VERSION "dbc-export 1 2025.20.8"

NS_ :

BS_:

BU_: APP APS DAS EPAS3S ESP GTW IBST PARK RADC RCM TPMS USM

BO_ 606 PARK_pscEnvSlot: 8 PARK
 SG_ PARK_pscEnvSlotType M : 0|2@1+ (1,0) [0|3] "" Vector__XXX
 SG_ PARK_pscLeftParallelObj1X m0 : 3|11@1+ (2,-2048) [-2048|2044] "cm" Vector__XXX
 SG_ PARK_pscLeftParallelObj1Y m0 : 14|11@1+ (2,-2048) [-2048|2044] "cm" Vector__XXX
 SG_ PARK_pscLeftParallelObj1Alpha m0 : 25|7@1+ (2,-128) [-128|124] "deg" Vector__XXX
 SG_ PARK_pscLeftParallelObj2Y m0 : 35|11@1+ (2,-2048) [-2048|2044] "cm" Vector__XXX
 SG_ PARK_pscLeftParallelObj2X m0 : 46|11@1+ (2,-2048) [-2048|2044] "cm" Vector__XXX
 SG_ PARK_pscLeftParallelObj2Alpha m0 : 57|7@1+ (2,-128) [-128|124] "deg" Vector__XXX
 SG_ PARK_pscLeftCrossObj1X m1 : 3|11@1+ (2,-2048) [-2048|2044] "cm" Vector__XXX
 SG_ PARK_pscLeftCrossObj1Y m1 : 14|11@1+ (2,-2048) [-2048|2044] "cm" Vector__XXX
 SG_ PARK_pscLeftCrossObj1Alpha m1 : 25|7@1+ (2,-128) [-128|124] "deg" Vector__XXX
 SG_ PARK_pscLeftCrossObj2Y m1 : 35|11@1+ (2,-2048) [-2048|2044] "cm" Vector__XXX
 SG_ PARK_pscLeftCrossObj2X m1 : 46|11@1+ (2,-2048) [-2048|2044] "cm" Vector__XXX
 SG_ PARK_pscLeftCrossObj2Alpha m1 : 57|7@1+ (2,-128) [-128|124] "deg" Vector__XXX
 SG_ PARK_pscRightParallelObj1X m2 : 3|11@1+ (2,-2048) [-2048|2044] "cm" Vector__XXX
 SG_ PARK_pscRightParallelObj1Y m2 : 14|11@1+ (2,-2048) [-2048|2044] "cm" Vector__XXX
 SG_ PARK_pscRightParallelObj1Alpha m2 : 25|7@1+ (2,-128) [-128|124] "deg" Vector__XXX
 SG_ PARK_pscRightParallelObj2Y m2 : 35|11@1+ (2,-2048) [-2048|2044] "cm" Vector__XXX
 SG_ PARK_pscRightParallelObj2X m2 : 46|11@1+ (2,-2048) [-2048|2044] "cm" Vector__XXX
 SG_ PARK_pscRightParallelObj2Alpha m2 : 57|7@1+ (2,-128) [-128|124] "deg" Vector__XXX
 SG_ PARK_pscRightCrossObj1X m3 : 3|11@1+ (2,-2048) [-2048|2044] "cm" Vector__XXX
 SG_ PARK_pscRightCrossObj1Y m3 : 14|11@1+ (2,-2048) [-2048|2044] "cm" Vector__XXX
 SG_ PARK_pscRightCrossObj1Alpha m3 : 25|7@1+ (2,-128) [-128|124] "deg" Vector__XXX
 SG_ PARK_pscRightCrossObj2Y m3 : 35|11@1+ (2,-2048) [-2048|2044] "cm" Vector__XXX
 SG_ PARK_pscRightCrossObj2X m3 : 46|11@1+ (2,-2048) [-2048|2044] "cm" Vector__XXX
 SG_ PARK_pscRightCrossObj2Alpha m3 : 57|7@1+ (2,-128) [-128|124] "deg" Vector__XXX

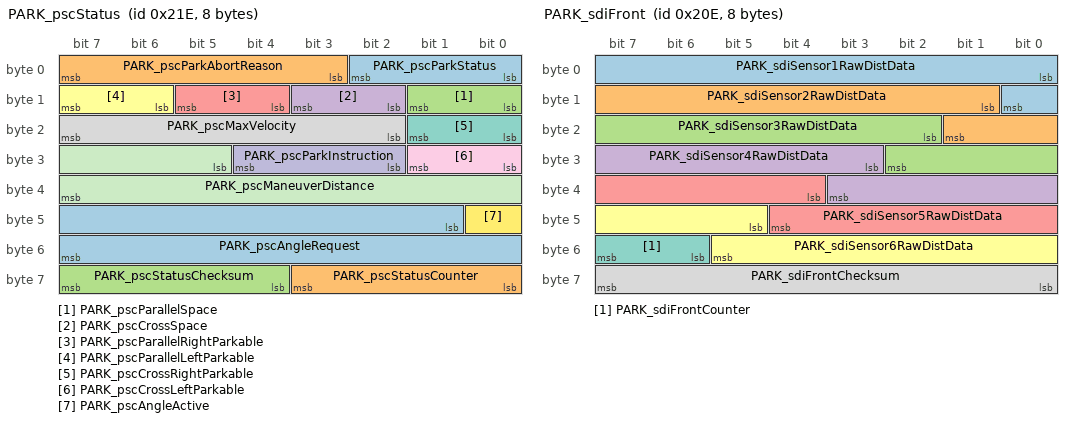
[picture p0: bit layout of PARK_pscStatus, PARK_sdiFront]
BO_ 542 PARK_pscStatus: 8 PARK
 SG_ PARK_pscParkStatus : 0|3@1+ (1,0) [0|6] "" Vector__XXX
 SG_ PARK_pscParkAbortReason : 3|5@1+ (1,0) [0|30] "" Vector__XXX
 SG_ PARK_pscParallelSpace : 8|2@1+ (1,0) [0|3] "" Vector__XXX
 SG_ PARK_pscCrossSpace : 10|2@1+ (1,0) [0|3] "" Vector__XXX
 SG_ PARK_pscParallelRightParkable : 12|2@1+ (1,0) [0|2] "" Vector__XXX
 SG_ PARK_pscParallelLeftParkable : 14|2@1+ (1,0) [0|2] "" Vector__XXX
 SG_ PARK_pscCrossRightParkable : 16|2@1+ (1,0) [0|2] "" Vector__XXX
 SG_ PARK_pscMaxVelocity : 18|6@1+ (0.1,0) [0|6.2] "kph" Vector__XXX
 SG_ PARK_pscCrossLeftParkable : 24|2@1+ (1,0) [0|2] "" Vector__XXX
 SG_ PARK_pscParkInstruction : 26|3@1+ (1,0) [0|6] "" Vector__XXX
 SG_ PARK_pscManeuverDistance : 29|11@1+ (1,0) [0|2046] "cm" Vector__XXX
 SG_ PARK_pscAngleActive : 40|1@1+ (1,0) [0|1] "" Vector__XXX
 SG_ PARK_pscAngleRequest : 41|15@1+ (0.1,-1638.4) [-1638.4|1638.3] "deg" Vector__XXX
 SG_ PARK_pscStatusCounter : 56|4@1+ (1,0) [0|15] "" Vector__XXX
 SG_ PARK_pscStatusChecksum : 60|4@1+ (1,0) [0|15] "" Vector__XXX

BO_ 590 PARK_pscVehSlot: 8 PARK
 SG_ PARK_pscVehSlotType M : 0|2@1+ (1,0) [0|3] "" Vector__XXX
 SG_ PARK_pscLeftParallelVehX m0 : 5|11@1+ (2,-2048) [-2048|2044] "cm" Vector__XXX
 SG_ PARK_pscLeftParallelVehY m0 : 16|11@1+ (2,-2048) [-2048|2044] "cm" Vector__XXX
 SG_ PARK_pscLeftParallelPsi m0 : 32|13@1+ (0.0009765625,0) [0|7.998046875] "radians" Vector__XXX
 SG_ PARK_pscLeftParallelSizeX m0 : 48|8@1+ (4,0) [0|1016] "cm" Vector__XXX
 SG_ PARK_pscLeftParallelSizeY m0 : 56|8@1+ (4,0) [0|1016] "cm" Vector__XXX
 SG_ PARK_pscLeftCrossVehX m1 : 5|11@1+ (2,-2048) [-2048|2044] "cm" Vector__XXX
 SG_ PARK_pscLeftCrossVehY m1 : 16|11@1+ (2,-2048) [-2048|2044] "cm" Vector__XXX
 SG_ PARK_pscLeftCrossPsi m1 : 32|13@1+ (0.0009765625,0) [0|7.998046875] "radians" Vector__XXX
 SG_ PARK_pscLeftCrossSizeX m1 : 48|8@1+ (4,0) [0|1016] "cm" Vector__XXX
 SG_ PARK_pscLeftCrossSizeY m1 : 56|8@1+ (4,0) [0|1016] "cm" Vector__XXX
 SG_ PARK_pscRightParallelVehX m2 : 5|11@1+ (2,-2048) [-2048|2044] "cm" Vector__XXX
 SG_ PARK_pscRightParallelVehY m2 : 16|11@1+ (2,-2048) [-2048|2044] "cm" Vector__XXX
 SG_ PARK_pscRightParallelPsi m2 : 32|13@1+ (0.0009765625,0) [0|7.998046875] "radians" Vector__XXX
 SG_ PARK_pscRightParallelSizeX m2 : 48|8@1+ (4,0) [0|1016] "cm" Vector__XXX
 SG_ PARK_pscRightParallelSizeY m2 : 56|8@1+ (4,0) [0|1016] "cm" Vector__XXX
 SG_ PARK_pscRightCrossVehX m3 : 5|11@1+ (2,-2048) [-2048|2044] "cm" Vector__XXX
 SG_ PARK_pscRightCrossVehY m3 : 16|11@1+ (2,-2048) [-2048|2044] "cm" Vector__XXX
 SG_ PARK_pscRightCrossPsi m3 : 32|13@1+ (0.0009765625,0) [0|7.998046875] "radians" Vector__XXX
 SG_ PARK_pscRightCrossSizeX m3 : 48|8@1+ (4,0) [0|1016] "cm" Vector__XXX
 SG_ PARK_pscRightCrossSizeY m3 : 56|8@1+ (4,0) [0|1016] "cm" Vector__XXX

BO_ 526 PARK_sdiFront: 8 PARK
 SG_ PARK_sdiSensor1RawDistData : 0|9@1+ (1,0) [0|510] "cm" Vector__XXX
 SG_ PARK_sdiSensor2RawDistData : 9|9@1+ (1,0) [0|510] "cm" Vector__XXX
 SG_ PARK_sdiSensor3RawDistData : 18|9@1+ (1,0) [0|510] "cm" Vector__XXX
 SG_ PARK_sdiSensor4RawDistData : 27|9@1+ (1,0) [0|510] "cm" Vector__XXX
 SG_ PARK_sdiSensor5RawDistData : 36|9@1+ (1,0) [0|510] "cm" Vector__XXX
 SG_ PARK_sdiSensor6RawDistData : 45|9@1+ (1,0) [0|510] "cm" Vector__XXX
 SG_ PARK_sdiFrontCounter : 54|2@1+ (1,0) [0|3] "" Vector__XXX
 SG_ PARK_sdiFrontChecksum : 56|8@1+ (1,0) [0|255] "" Vector__XXX

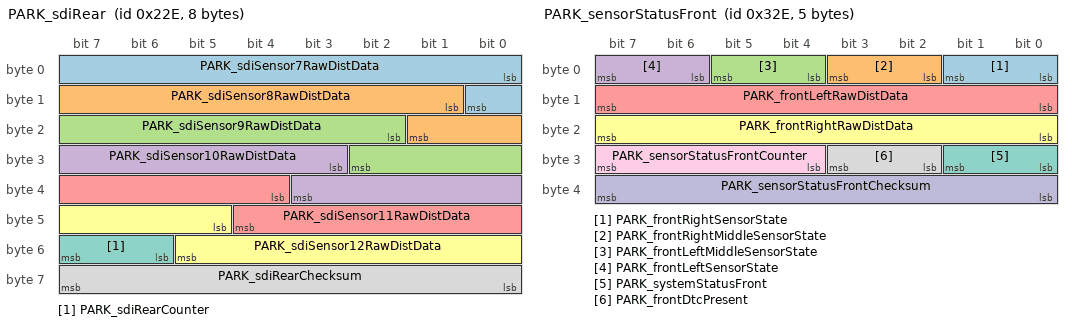
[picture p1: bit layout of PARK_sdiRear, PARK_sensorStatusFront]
BO_ 558 PARK_sdiRear: 8 PARK
 SG_ PARK_sdiSensor7RawDistData : 0|9@1+ (1,0) [0|510] "cm" Vector__XXX
 SG_ PARK_sdiSensor8RawDistData : 9|9@1+ (1,0) [0|510] "cm" Vector__XXX
 SG_ PARK_sdiSensor9RawDistData : 18|9@1+ (1,0) [0|510] "cm" Vector__XXX
 SG_ PARK_sdiSensor10RawDistData : 27|9@1+ (1,0) [0|510] "cm" Vector__XXX
 SG_ PARK_sdiSensor11RawDistData : 36|9@1+ (1,0) [0|510] "cm" Vector__XXX
 SG_ PARK_sdiSensor12RawDistData : 45|9@1+ (1,0) [0|510] "cm" Vector__XXX
 SG_ PARK_sdiRearCounter : 54|2@1+ (1,0) [0|3] "" Vector__XXX
 SG_ PARK_sdiRearChecksum : 56|8@1+ (1,0) [0|255] "" Vector__XXX

BO_ 814 PARK_sensorStatusFront: 5 PARK
 SG_ PARK_frontRightSensorState : 0|2@1+ (1,0) [0|2] "" Vector__XXX
 SG_ PARK_frontRightMiddleSensorState : 2|2@1+ (1,0) [0|2] "" Vector__XXX
 SG_ PARK_frontLeftMiddleSensorState : 4|2@1+ (1,0) [0|2] "" Vector__XXX
 SG_ PARK_frontLeftSensorState : 6|2@1+ (1,0) [0|2] "" Vector__XXX
 SG_ PARK_frontLeftRawDistData : 8|8@1+ (1,0) [0|254] "cm" Vector__XXX
 SG_ PARK_frontRightRawDistData : 16|8@1+ (1,0) [0|254] "cm" Vector__XXX
 SG_ PARK_systemStatusFront : 24|2@1+ (1,0) [0|2] "" Vector__XXX
 SG_ PARK_frontDtcPresent : 26|2@1+ (1,0) [0|2] "" Vector__XXX
 SG_ PARK_sensorStatusFrontCounter : 28|4@1+ (1,0) [0|15] "" Vector__XXX
 SG_ PARK_sensorStatusFrontChecksum : 32|8@1+ (1,0) [0|255] "" Vector__XXX

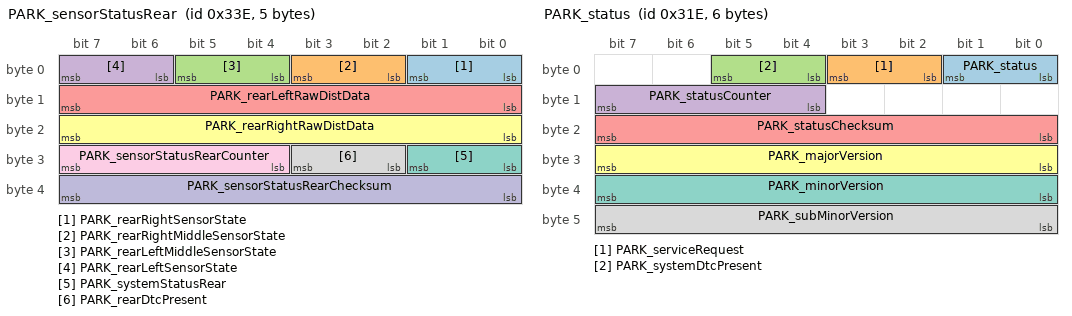
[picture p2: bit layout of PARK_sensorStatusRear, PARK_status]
BO_ 830 PARK_sensorStatusRear: 5 PARK
 SG_ PARK_rearRightSensorState : 0|2@1+ (1,0) [0|2] "" Vector__XXX
 SG_ PARK_rearRightMiddleSensorState : 2|2@1+ (1,0) [0|2] "" Vector__XXX
 SG_ PARK_rearLeftMiddleSensorState : 4|2@1+ (1,0) [0|2] "" Vector__XXX
 SG_ PARK_rearLeftSensorState : 6|2@1+ (1,0) [0|2] "" Vector__XXX
 SG_ PARK_rearLeftRawDistData : 8|8@1+ (1,0) [0|254] "cm" Vector__XXX
 SG_ PARK_rearRightRawDistData : 16|8@1+ (1,0) [0|254] "cm" Vector__XXX
 SG_ PARK_systemStatusRear : 24|2@1+ (1,0) [0|2] "" Vector__XXX
 SG_ PARK_rearDtcPresent : 26|2@1+ (1,0) [0|2] "" Vector__XXX
 SG_ PARK_sensorStatusRearCounter : 28|4@1+ (1,0) [0|15] "" Vector__XXX
 SG_ PARK_sensorStatusRearChecksum : 32|8@1+ (1,0) [0|255] "" Vector__XXX

BO_ 798 PARK_status: 6 PARK
 SG_ PARK_status : 0|2@1+ (1,0) [0|2] "" Vector__XXX
 SG_ PARK_serviceRequest : 2|2@1+ (1,0) [0|2] "" Vector__XXX
 SG_ PARK_systemDtcPresent : 4|2@1+ (1,0) [0|2] "" Vector__XXX
 SG_ PARK_statusCounter : 12|4@1+ (1,0) [0|15] "" Vector__XXX
 SG_ PARK_statusChecksum : 16|8@1+ (1,0) [0|255] "" Vector__XXX
 SG_ PARK_majorVersion : 24|8@1+ (1,0) [0|254] "" Vector__XXX
 SG_ PARK_minorVersion : 32|8@1+ (1,0) [0|254] "" Vector__XXX
 SG_ PARK_subMinorVersion : 40|8@1+ (1,0) [0|254] "" Vector__XXX

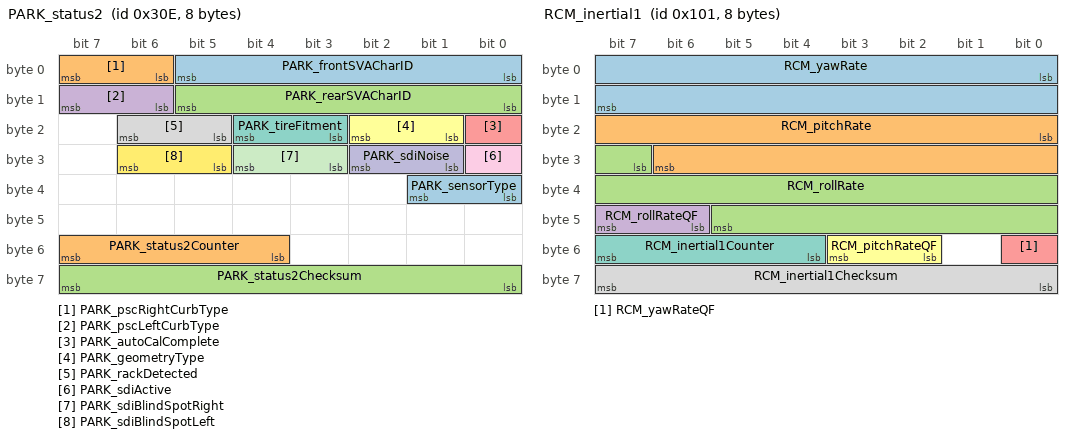
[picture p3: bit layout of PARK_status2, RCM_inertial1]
BO_ 782 PARK_status2: 8 PARK
 SG_ PARK_frontSVACharID : 0|6@1+ (1,0) [0|63] "" Vector__XXX
 SG_ PARK_pscRightCurbType : 6|2@1+ (1,0) [0|3] "" Vector__XXX
 SG_ PARK_rearSVACharID : 8|6@1+ (1,0) [0|63] "" Vector__XXX
 SG_ PARK_pscLeftCurbType : 14|2@1+ (1,0) [0|3] "" Vector__XXX
 SG_ PARK_autoCalComplete : 16|1@1+ (1,0) [0|1] "" Vector__XXX
 SG_ PARK_geometryType : 17|2@1+ (1,0) [0|3] "" Vector__XXX
 SG_ PARK_tireFitment : 19|2@1+ (1,0) [0|2] "" Vector__XXX
 SG_ PARK_rackDetected : 21|2@1+ (1,0) [0|2] "" Vector__XXX
 SG_ PARK_sdiActive : 24|1@1+ (1,0) [0|1] "" Vector__XXX
 SG_ PARK_sdiNoise : 25|2@1+ (1,0) [0|2] "" Vector__XXX
 SG_ PARK_sdiBlindSpotRight : 27|2@1+ (1,0) [0|2] "" Vector__XXX
 SG_ PARK_sdiBlindSpotLeft : 29|2@1+ (1,0) [0|2] "" Vector__XXX
 SG_ PARK_sensorType : 32|2@1+ (1,0) [0|2] "" Vector__XXX
 SG_ PARK_status2Counter : 52|4@1+ (1,0) [0|15] "" Vector__XXX
 SG_ PARK_status2Checksum : 56|8@1+ (1,0) [0|255] "" Vector__XXX

BO_ 1329 RADC_info: 8 RADC
 SG_ RADC_infoIndex M : 0|8@1+ (1,0) [0|255] "" Vector__XXX
 SG_ RADC_infoBuildType m10 : 8|8@1+ (1,0) [0|255] "" Vector__XXX
 SG_ RADC_infoBuildConfigID m10 : 16|16@1+ (1,0) [0|65535] "" Vector__XXX
 SG_ RADC_infoHardwareID m10 : 32|16@1+ (1,0) [0|65535] "" Vector__XXX
 SG_ RADC_infoComponentID m10 : 48|16@1+ (1,0) [0|65535] "" Vector__XXX
 SG_ RADC_infoPcbaID m11 : 16|8@1+ (1,0) [0|255] "" Vector__XXX
 SG_ RADC_infoAssemblyID m11 : 24|8@1+ (1,0) [0|255] "" Vector__XXX
 SG_ RADC_infoUsageID m11 : 32|16@1+ (1,0) [0|65535] "" Vector__XXX
 SG_ RADC_infoSubUsageID m11 : 48|16@1+ (1,0) [0|65535] "" Vector__XXX
 SG_ RADC_infoApplicationCRC m13 : 32|32@1+ (1,0) [0|4294967295] "" Vector__XXX
 SG_ RADC_infoPlatformType m19 : 8|8@1+ (1,0) [0|255] "" Vector__XXX
 SG_ RADC_infoMajorVersion m19 : 16|8@1+ (1,0) [0|255] "" Vector__XXX
 SG_ RADC_infoBranchOrigin m19 : 24|8@1+ (1,0) [0|255] "" Vector__XXX
 SG_ RADC_infoMaturity m19 : 32|8@1+ (1,0) [0|255] "" Vector__XXX
 SG_ RADC_infoHardwareRevision m19 : 40|8@1+ (1,0) [0|255] "" Vector__XXX
 SG_ RADC_infoBootUdsProtoVersion m20 : 8|8@1+ (1,0) [0|255] "" Vector__XXX
 SG_ RADC_infoBootloaderCRC m20 : 32|32@1+ (1,0) [0|4294967295] "" Vector__XXX

BO_ 257 RCM_inertial1: 8 RCM
 SG_ RCM_yawRate : 0|16@1- (0.0001,0) [-3.2766|3.2766] "rad/s" Vector__XXX
 SG_ RCM_pitchRate : 16|15@1- (0.00025,0) [-4.096|4.09575] "rad/s" Vector__XXX
 SG_ RCM_rollRate : 31|15@1- (0.00025,0) [-4.096|4.09575] "rad/s" Vector__XXX
 SG_ RCM_rollRateQF : 46|2@1+ (1,0) [0|3] "" Vector__XXX
 SG_ RCM_yawRateQF : 48|1@1+ (1,0) [0|1] "" Vector__XXX
 SG_ RCM_pitchRateQF : 50|2@1+ (1,0) [0|3] "" Vector__XXX
 SG_ RCM_inertial1Counter : 52|4@1+ (1,0) [0|15] "" Vector__XXX
 SG_ RCM_inertial1Checksum : 56|8@1+ (1,0) [0|255] "" Vector__XXX

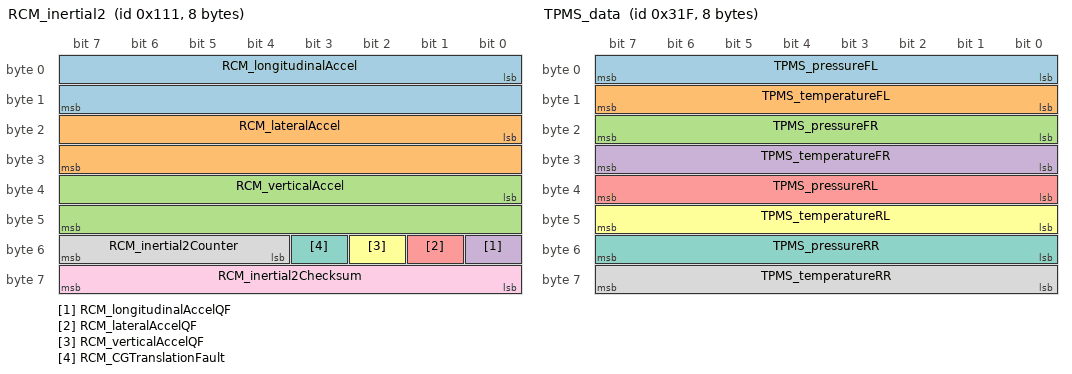
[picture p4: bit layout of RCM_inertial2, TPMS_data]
BO_ 273 RCM_inertial2: 8 RCM
 SG_ RCM_longitudinalAccel : 0|16@1- (0.00125,0) [-40.9575|40.9575] "m/s^2" Vector__XXX
 SG_ RCM_lateralAccel : 16|16@1- (0.00125,0) [-40.9575|40.9575] "m/s^2" Vector__XXX
 SG_ RCM_verticalAccel : 32|16@1- (0.00125,0) [-40.9575|39.2] "m/s^2" Vector__XXX
 SG_ RCM_longitudinalAccelQF : 48|1@1+ (1,0) [0|1] "" Vector__XXX
 SG_ RCM_lateralAccelQF : 49|1@1+ (1,0) [0|1] "" Vector__XXX
 SG_ RCM_verticalAccelQF : 50|1@1+ (1,0) [0|1] "" Vector__XXX
 SG_ RCM_CGTranslationFault : 51|1@1+ (1,0) [0|1] "" Vector__XXX
 SG_ RCM_inertial2Counter : 52|4@1+ (1,0) [0|15] "" Vector__XXX
 SG_ RCM_inertial2Checksum : 56|8@1+ (1,0) [0|255] "" Vector__XXX

BO_ 849 RCM_info: 8 RCM
 SG_ RCM_infoIndex M : 0|8@1+ (1,0) [0|255] "" Vector__XXX
 SG_ RCM_infoBuildType m10 : 8|8@1+ (1,0) [0|255] "" Vector__XXX
 SG_ RCM_infoComponentID m10 : 48|16@1+ (1,0) [0|65535] "" Vector__XXX
 SG_ RCM_infoPcbaID m11 : 16|8@1+ (1,0) [0|255] "" Vector__XXX
 SG_ RCM_infoAssemblyID m11 : 24|8@1+ (1,0) [0|255] "" Vector__XXX
 SG_ RCM_infoUsageID m11 : 32|16@1+ (1,0) [0|65535] "" Vector__XXX
 SG_ RCM_infoApplicationCRC m13 : 32|32@1+ (1,0) [0|4294967295] "" Vector__XXX
 SG_ RCM_infoBootUdsProtoVersion m20 : 8|8@1+ (1,0) [0|255] "" Vector__XXX
 SG_ RCM_infoBootloaderCRC m20 : 32|32@1+ (1,0) [0|4294967295] "" Vector__XXX
 SG_ RCM_infoAlgoCalID m22 : 8|8@1+ (1,0) [0|255] "" Vector__XXX
 SG_ RCM_infoVariantCRC m22 : 32|32@1+ (1,0) [0|4294967295] "" Vector__XXX

BO_ 529 RCM_status: 6 RCM
 SG_ RCM_statusChecksum : 0|8@1+ (1,0) [0|255] "" Vector__XXX
 SG_ RCM_statusCounter : 8|4@1+ (1,0) [0|15] "" Vector__XXX
 SG_ RCM_armStatus : 12|2@1+ (1,0) [0|2] "" Vector__XXX
 SG_ RCM_warningIndicatorState : 14|2@1+ (1,0) [0|2] "" Vector__XXX
 SG_ RCM_passAirbagIndicatorRequest : 16|2@1+ (1,0) [0|2] "" Vector__XXX
 SG_ RCM_airbagCutoffStatus : 18|2@1+ (1,0) [0|2] "" Vector__XXX
 SG_ RCM_alrSwitchStatus : 20|2@1+ (1,0) [0|2] "" Vector__XXX
 SG_ RCM_vinLearnFlag : 22|2@1+ (1,0) [0|2] "" Vector__XXX
 SG_ RCM_seatTrackPositionDrvr : 24|2@1+ (1,0) [0|2] "" Vector__XXX
 SG_ RCM_seatTrackPositionPass : 26|2@1+ (1,0) [0|2] "" Vector__XXX
 SG_ RCM_edr1State : 28|2@1+ (1,0) [0|3] "" Vector__XXX
 SG_ RCM_edr2State : 30|2@1+ (1,0) [0|3] "" Vector__XXX
 SG_ RCM_keepPowerReason : 32|4@1+ (1,0) [0|15] "" Vector__XXX
 SG_ RCM_imuOffsetLearnState : 36|2@1+ (1,0) [0|3] "" Vector__XXX
 SG_ RCM_edr3State : 38|2@1+ (1,0) [0|3] "" Vector__XXX
 SG_ RCM_driverOrientationInitStatus : 40|3@1+ (1,0) [0|6] "" Vector__XXX
 SG_ RCM_occupantClassificationSource : 43|1@1+ (1,0) [0|1] "" Vector__XXX
 SG_ RCM_pedProEDR1State : 44|2@1+ (1,0) [0|3] "" Vector__XXX
 SG_ RCM_pedProEDR2State : 46|2@1+ (1,0) [0|3] "" Vector__XXX

BO_ 879 TPMS_StatusC: 8 TPMS
 SG_ TPMS_c_globalHardWarning : 0|1@1+ (1,0) [0|1] "" Vector__XXX
 SG_ TPMS_c_globalSoftWarning : 1|1@1+ (1,0) [0|1] "" Vector__XXX
 SG_ TPMS_systemMalfunction : 2|1@1+ (1,0) [0|1] "" Vector__XXX
 SG_ TPMS_WA_version : 3|1@1+ (1,0) [0|1] "" Vector__XXX
 SG_ TPMS_globalDeltaPressure : 4|1@1+ (1,0) [0|1] "" Vector__XXX
 SG_ TPMS_newSensorLearnt : 5|3@1+ (1,0) [0|7] "" Vector__XXX
 SG_ TPMS_softWarningRR : 8|1@1+ (1,0) [0|1] "" Vector__XXX
 SG_ TPMS_hardWarningRR : 9|1@1+ (1,0) [0|1] "" Vector__XXX
 SG_ TPMS_softWarningRL : 10|1@1+ (1,0) [0|1] "" Vector__XXX
 SG_ TPMS_hardWarningRL : 11|1@1+ (1,0) [0|1] "" Vector__XXX
 SG_ TPMS_softWarningFR : 12|1@1+ (1,0) [0|1] "" Vector__XXX
 SG_ TPMS_hardWarningFR : 13|1@1+ (1,0) [0|1] "" Vector__XXX
 SG_ TPMS_softWarningFL : 14|1@1+ (1,0) [0|1] "" Vector__XXX
 SG_ TPMS_hardWarningFL : 15|1@1+ (1,0) [0|1] "" Vector__XXX
 SG_ TPMS_learningStatus : 16|2@1+ (1,0) [0|3] "" Vector__XXX
 SG_ TPMS_localisationStatus : 18|2@1+ (1,0) [0|3] "" Vector__XXX
 SG_ TPMS_deltaPressWarningFL : 20|1@1+ (1,0) [0|1] "" Vector__XXX
 SG_ TPMS_deltaPressWarningFR : 21|1@1+ (1,0) [0|1] "" Vector__XXX
 SG_ TPMS_deltaPressWarningRL : 22|1@1+ (1,0) [0|1] "" Vector__XXX
 SG_ TPMS_deltaPressWarningRR : 23|1@1+ (1,0) [0|1] "" Vector__XXX
 SG_ TPMS_sensorNoResponseFL : 24|1@1+ (1,0) [0|1] "" Vector__XXX
 SG_ TPMS_sensorNoResponseFR : 25|1@1+ (1,0) [0|1] "" Vector__XXX
 SG_ TPMS_sensorNoResponseRL : 26|1@1+ (1,0) [0|1] "" Vector__XXX
 SG_ TPMS_sensorNoResponseRR : 27|1@1+ (1,0) [0|1] "" Vector__XXX
 SG_ TPMS_sensorThermShutdownFL : 28|1@1+ (1,0) [0|1] "" Vector__XXX
 SG_ TPMS_sensorThermShutdownFR : 29|1@1+ (1,0) [0|1] "" Vector__XXX
 SG_ TPMS_sensorThermShutdownRL : 30|1@1+ (1,0) [0|1] "" Vector__XXX
 SG_ TPMS_sensorThermShutdownRR : 31|1@1+ (1,0) [0|1] "" Vector__XXX
 SG_ TPMS_sensorBatteryLowFL : 32|1@1+ (1,0) [0|1] "" Vector__XXX
 SG_ TPMS_sensorBatteryLowFR : 33|1@1+ (1,0) [0|1] "" Vector__XXX
 SG_ TPMS_sensorBatteryLowRL : 34|1@1+ (1,0) [0|1] "" Vector__XXX
 SG_ TPMS_sensorBatteryLowRR : 35|1@1+ (1,0) [0|1] "" Vector__XXX
 SG_ TPMS_sensorDefectiveFL : 36|1@1+ (1,0) [0|1] "" Vector__XXX
 SG_ TPMS_sensorDefectiveFR : 37|1@1+ (1,0) [0|1] "" Vector__XXX
 SG_ TPMS_sensorDefectiveRL : 38|1@1+ (1,0) [0|1] "" Vector__XXX
 SG_ TPMS_sensorDefectiveRR : 39|1@1+ (1,0) [0|1] "" Vector__XXX
 SG_ TPMS_ecuUnderVoltage : 40|1@1+ (1,0) [0|1] "" Vector__XXX
 SG_ TPMS_ecuOverVoltage : 41|1@1+ (1,0) [0|1] "" Vector__XXX
 SG_ TPMS_ecuRamRomNvMFail : 42|1@1+ (1,0) [0|1] "" Vector__XXX
 SG_ TPMS_rfReceiverFail : 43|1@1+ (1,0) [0|1] "" Vector__XXX
 SG_ TPMS_wheelPulseMissing : 44|1@1+ (1,0) [0|1] "" Vector__XXX
 SG_ TPMS_vehicleSpeedFail : 45|1@1+ (1,0) [0|1] "" Vector__XXX
 SG_ TPMS_externalTemperatureFail : 46|1@1+ (1,0) [0|1] "" Vector__XXX
 SG_ TPMS_eolNotCompleted : 47|1@1+ (1,0) [0|1] "" Vector__XXX
 SG_ TPMS_rcpFront : 48|8@1+ (0.025,0) [0|6.375] "bar" Vector__XXX
 SG_ TPMS_rcpRear : 56|8@1+ (0.025,0) [0|6.375] "bar" Vector__XXX

BO_ 799 TPMS_data: 8 TPMS
 SG_ TPMS_pressureFL : 0|8@1+ (0.025,0) [0|6.35] "bar" Vector__XXX
 SG_ TPMS_temperatureFL : 8|8@1+ (1,-40) [-40|214] "degC" Vector__XXX
 SG_ TPMS_pressureFR : 16|8@1+ (0.025,0) [0|6.35] "bar" Vector__XXX
 SG_ TPMS_temperatureFR : 24|8@1+ (1,-40) [-40|214] "degC" Vector__XXX
 SG_ TPMS_pressureRL : 32|8@1+ (0.025,0) [0|6.35] "bar" Vector__XXX
 SG_ TPMS_temperatureRL : 40|8@1+ (1,-40) [-40|214] "degC" Vector__XXX
 SG_ TPMS_pressureRR : 48|8@1+ (0.025,0) [0|6.35] "bar" Vector__XXX
 SG_ TPMS_temperatureRR : 56|8@1+ (1,-40) [-40|214] "degC" Vector__XXX

BO_ 1519 TPMS_info: 8 TPMS
 SG_ TPMS_infoIndex M : 0|8@1+ (1,0) [0|255] "" Vector__XXX
 SG_ TPMS_infoComponentID m10 : 48|16@1+ (1,0) [0|65535] "" Vector__XXX
 SG_ TPMS_infoPcbaID m11 : 16|8@1+ (1,0) [0|255] "" Vector__XXX
 SG_ TPMS_infoAssemblyID m11 : 24|8@1+ (1,0) [0|255] "" Vector__XXX
 SG_ TPMS_infoUsageID m11 : 32|16@1+ (1,0) [0|65535] "" Vector__XXX
 SG_ TPMS_infoApplicationCRC m13 : 32|32@1+ (1,0) [0|4294967295] "" Vector__XXX
 SG_ TPMS_infoBootUdsProtoVersion m20 : 8|8@1+ (1,0) [0|255] "" Vector__XXX
 SG_ TPMS_infoBootloaderCRC m20 : 32|32@1+ (1,0) [0|4294967295] "" Vector__XXX

BO_ 659 UI_chassisControl: 8 GTW
 SG_ UI_steeringTuneRequest : 0|2@1+ (1,0) [0|3] "" Vector__XXX
 SG_ UI_tractionControlMode : 2|3@1+ (1,0) [0|7] "" Vector__XXX
 SG_ UI_parkBrakeRequest : 5|2@1+ (1,0) [0|2] "" Vector__XXX
 SG_ UI_winchModeRequest : 8|2@1+ (1,0) [0|3] "" Vector__XXX
 SG_ UI_trailerMode : 12|1@1+ (1,0) [0|1] "" Vector__XXX
 SG_ UI_accOvertakeEnable : 16|2@1+ (1,0) [0|2] "" Vector__XXX
 SG_ UI_aebEnable : 18|2@1+ (1,0) [0|2] "" Vector__XXX
 SG_ UI_aesEnable : 20|2@1+ (1,0) [0|2] "" Vector__XXX
 SG_ UI_ahlbEnable : 22|2@1+ (1,0) [0|2] "" Vector__XXX
 SG_ UI_autoLaneChangeEnable : 24|2@1+ (1,0) [0|2] "" Vector__XXX
 SG_ UI_winchProxUserOverride : 26|1@1+ (1,0) [0|1] "" Vector__XXX
 SG_ UI_autoParkRequest : 28|4@1+ (1,0) [0|14] "" Vector__XXX
 SG_ UI_bsdEnable : 32|2@1+ (1,0) [0|2] "" Vector__XXX
 SG_ UI_fcwEnable : 34|2@1+ (1,0) [0|2] "" Vector__XXX
 SG_ UI_fcwSensitivity : 36|2@1+ (1,0) [0|2] "" Vector__XXX
 SG_ UI_latControlEnable : 38|2@1+ (1,0) [0|2] "" Vector__XXX
 SG_ UI_ldwEnable : 40|2@1+ (1,0) [0|2] "" Vector__XXX

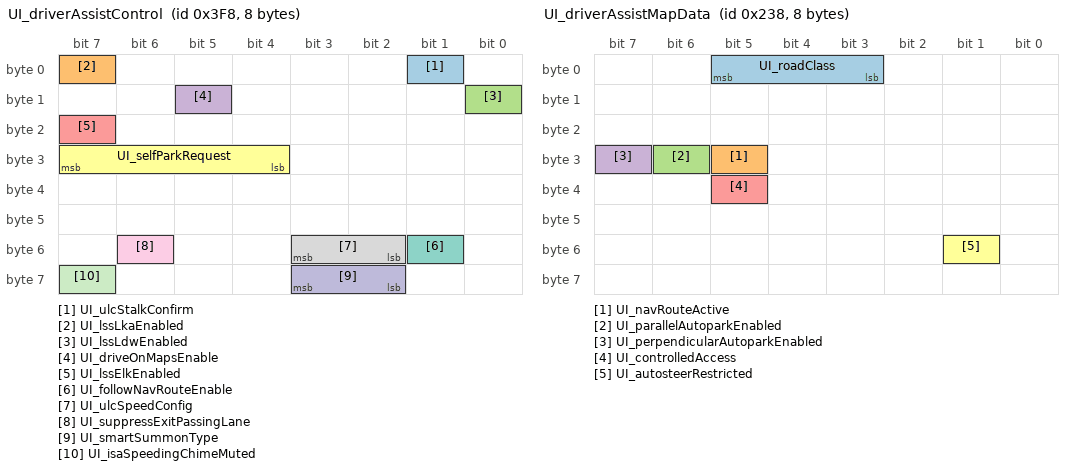
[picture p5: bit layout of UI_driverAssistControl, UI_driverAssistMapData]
BO_ 1016 UI_driverAssistControl: 8 GTW
 SG_ UI_ulcStalkConfirm : 1|1@1+ (1,0) [0|1] "" Vector__XXX
 SG_ UI_lssLkaEnabled : 7|1@1+ (1,0) [0|1] "" Vector__XXX
 SG_ UI_lssLdwEnabled : 8|1@1+ (1,0) [0|1] "" Vector__XXX
 SG_ UI_driveOnMapsEnable : 13|1@1+ (1,0) [0|1] "" Vector__XXX
 SG_ UI_lssElkEnabled : 23|1@1+ (1,0) [0|1] "" Vector__XXX
 SG_ UI_selfParkRequest : 28|4@1+ (1,0) [0|14] "" Vector__XXX
 SG_ UI_followNavRouteEnable : 49|1@1+ (1,0) [0|1] "" Vector__XXX
 SG_ UI_ulcSpeedConfig : 50|2@1+ (1,0) [0|3] "" Vector__XXX
 SG_ UI_suppressExitPassingLane : 54|1@1+ (1,0) [0|1] "" Vector__XXX
 SG_ UI_smartSummonType : 58|2@1+ (1,0) [0|3] "" Vector__XXX
 SG_ UI_isaSpeedingChimeMuted : 63|1@1+ (1,0) [0|1] "" Vector__XXX

BO_ 568 UI_driverAssistMapData: 8 GTW
 SG_ UI_roadClass : 3|3@1+ (1,0) [1|7] "" Vector__XXX
 SG_ UI_navRouteActive : 29|1@1+ (1,0) [0|1] "" Vector__XXX
 SG_ UI_parallelAutoparkEnabled : 30|1@1+ (1,0) [0|1] "" Vector__XXX
 SG_ UI_perpendicularAutoparkEnabled : 31|1@1+ (1,0) [0|1] "" Vector__XXX
 SG_ UI_controlledAccess : 37|1@1+ (1,0) [0|1] "" Vector__XXX
 SG_ UI_autosteerRestricted : 49|1@1+ (1,0) [0|1] "" Vector__XXX

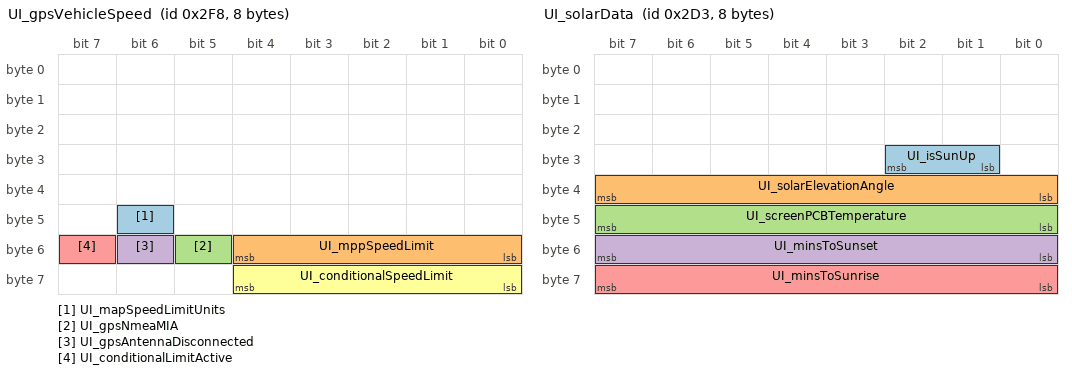
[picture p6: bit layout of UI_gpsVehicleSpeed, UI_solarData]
BO_ 760 UI_gpsVehicleSpeed: 8 GTW
 SG_ UI_mapSpeedLimitUnits : 46|1@1+ (1,0) [0|1] "" Vector__XXX
 SG_ UI_mppSpeedLimit : 48|5@1+ (5,0) [0|155] "kph/mph" Vector__XXX
 SG_ UI_gpsNmeaMIA : 53|1@1+ (1,0) [0|1] "" Vector__XXX
 SG_ UI_gpsAntennaDisconnected : 54|1@1+ (1,0) [0|1] "" Vector__XXX
 SG_ UI_conditionalLimitActive : 55|1@1+ (1,0) [0|1] "" Vector__XXX
 SG_ UI_conditionalSpeedLimit : 56|5@1+ (5,0) [0|150] "kph/mph" Vector__XXX

BO_ 1011 UI_odo: 3 GTW
 SG_ UI_odometer : 0|24@1+ (0.1,0) [0|1677721.4] "km" Vector__XXX

BO_ 723 UI_solarData: 8 GTW
 SG_ UI_isSunUp : 25|2@1+ (1,0) [0|2] "" Vector__XXX
 SG_ UI_solarElevationAngle : 32|8@1- (1,0) [-128|126] "degrees" Vector__XXX
 SG_ UI_screenPCBTemperature : 40|8@1- (0.5,40) [-20|100] "degC" Vector__XXX
 SG_ UI_minsToSunset : 48|8@1+ (10,0) [0|2550] "min" Vector__XXX
 SG_ UI_minsToSunrise : 56|8@1+ (10,0) [0|2550] "min" Vector__XXX

BO_ 851 UI_status: 8 GTW
 SG_ UI_touchActive : 0|1@1+ (1,0) [0|1] "" Vector__XXX
 SG_ UI_audioActive : 1|1@1+ (1,0) [0|1] "" Vector__XXX
 SG_ UI_cellActive : 3|1@1+ (1,0) [0|1] "" Vector__XXX
 SG_ UI_displayReady : 4|1@1+ (1,0) [0|1] "" Vector__XXX
 SG_ UI_displayOn : 5|1@1+ (1,0) [0|1] "" Vector__XXX
 SG_ UI_wifiActive : 6|1@1+ (1,0) [0|1] "" Vector__XXX
 SG_ UI_wifiConnected : 7|1@1+ (1,0) [0|1] "" Vector__XXX
 SG_ UI_readyForDrive : 9|1@1+ (1,0) [0|1] "" Vector__XXX
 SG_ UI_cellConnected : 10|1@1+ (1,0) [0|1] "" Vector__XXX
 SG_ UI_vpnActive : 11|1@1+ (1,0) [0|1] "" Vector__XXX
 SG_ UI_factoryReset : 14|2@1+ (1,0) [1|3] "" Vector__XXX
 SG_ UI_gpsActive : 16|1@1+ (1,0) [0|1] "" Vector__XXX
 SG_ UI_cellNetworkTechnology : 19|4@1+ (1,0) [0|14] "" Vector__XXX
 SG_ UI_falseTouchCounter : 32|8@1+ (1,0) [0|255] "1" Vector__XXX
 SG_ UI_cellSignalBars : 42|3@1+ (1,0) [0|6] "" Vector__XXX
 SG_ UI_trailerModeTelltale : 45|2@1+ (1,0) [0|3] "" Vector__XXX
 SG_ UI_pcbTemperature : 48|8@1- (1,40) [-20|100] "degC" Vector__XXX
 SG_ UI_cpuTemperature : 56|8@1- (1,40) [-20|100] "degC" Vector__XXX

BO_ 807 USM_info: 8 USM
 SG_ USM_infoIndex M : 0|8@1+ (1,0) [0|255] "" Vector__XXX
 SG_ USM_infoBuildType m10 : 8|3@1+ (1,0) [0|7] "" Vector__XXX
 SG_ USM_infoBuildConfigId m10 : 16|16@1+ (1,0) [0|65535] "" Vector__XXX
 SG_ USM_infoHardwareId m10 : 32|16@1+ (1,0) [0|65535] "" Vector__XXX
 SG_ USM_infoComponentId m10 : 48|16@1+ (1,0) [0|65535] "" Vector__XXX
 SG_ USM_infoPcbaId m11 : 8|8@1+ (1,0) [0|255] "" Vector__XXX
 SG_ USM_infoAssemblyId m11 : 16|8@1+ (1,0) [0|254] "" Vector__XXX
 SG_ USM_infoUsageId m11 : 24|16@1+ (1,0) [0|65535] "" Vector__XXX
 SG_ USM_infoSubUsageId m11 : 40|16@1+ (1,0) [0|65535] "" Vector__XXX
 SG_ USM_infoAppCrc m13 : 8|32@1+ (1,0) [0|4294967295] "" Vector__XXX

BO_TX_BU_ 606 : PARK;
BO_TX_BU_ 542 : PARK;
BO_TX_BU_ 590 : PARK;
BO_TX_BU_ 526 : PARK;
BO_TX_BU_ 558 : PARK;
BO_TX_BU_ 814 : PARK;
BO_TX_BU_ 830 : PARK;
BO_TX_BU_ 798 : PARK;
BO_TX_BU_ 782 : PARK;
BO_TX_BU_ 1329 : RADC;
BO_TX_BU_ 257 : RCM;
BO_TX_BU_ 273 : RCM;
BO_TX_BU_ 849 : RCM;
BO_TX_BU_ 529 : RCM;
BO_TX_BU_ 879 : TPMS;
BO_TX_BU_ 799 : TPMS;
BO_TX_BU_ 1519 : TPMS;
BO_TX_BU_ 659 : GTW;
BO_TX_BU_ 1016 : GTW;
BO_TX_BU_ 568 : GTW;
BO_TX_BU_ 760 : GTW;
BO_TX_BU_ 1011 : GTW;
BO_TX_BU_ 723 : GTW;
BO_TX_BU_ 851 : GTW;
BO_TX_BU_ 807 : USM;
CM_ BO_ 606 "Parking assist sensors message: psc env slot";
CM_ SG_ 606 PARK_pscEnvSlotType "Parking assist sensors: psc env slot type";
CM_ SG_ 606 PARK_pscLeftParallelObj1X "Parking assist sensors: psc left parallel obj1 x; raw 2047 = signal not available (SNA)";
CM_ SG_ 606 PARK_pscLeftParallelObj1Y "Parking assist sensors: psc left parallel obj1 y; raw 2047 = signal not available (SNA)";
CM_ SG_ 606 PARK_pscLeftParallelObj1Alpha "Parking assist sensors: psc left parallel obj1 alpha; raw 127 = signal not available (SNA)";
CM_ SG_ 606 PARK_pscLeftParallelObj2Y "Parking assist sensors: psc left parallel obj2 y; raw 2047 = signal not available (SNA)";
CM_ SG_ 606 PARK_pscLeftParallelObj2X "Parking assist sensors: psc left parallel obj2 x; raw 2047 = signal not available (SNA)";
CM_ SG_ 606 PARK_pscLeftParallelObj2Alpha "Parking assist sensors: psc left parallel obj2 alpha; raw 127 = signal not available (SNA)";
CM_ SG_ 606 PARK_pscLeftCrossObj1X "Parking assist sensors: psc left cross obj1 x; raw 2047 = signal not available (SNA)";
CM_ SG_ 606 PARK_pscLeftCrossObj1Y "Parking assist sensors: psc left cross obj1 y; raw 2047 = signal not available (SNA)";
CM_ SG_ 606 PARK_pscLeftCrossObj1Alpha "Parking assist sensors: psc left cross obj1 alpha; raw 127 = signal not available (SNA)";
CM_ SG_ 606 PARK_pscLeftCrossObj2Y "Parking assist sensors: psc left cross obj2 y; raw 2047 = signal not available (SNA)";
CM_ SG_ 606 PARK_pscLeftCrossObj2X "Parking assist sensors: psc left cross obj2 x; raw 2047 = signal not available (SNA)";
CM_ SG_ 606 PARK_pscLeftCrossObj2Alpha "Parking assist sensors: psc left cross obj2 alpha; raw 127 = signal not available (SNA)";
CM_ SG_ 606 PARK_pscRightParallelObj1X "Parking assist sensors: psc right parallel obj1 x; raw 2047 = signal not available (SNA)";
CM_ SG_ 606 PARK_pscRightParallelObj1Y "Parking assist sensors: psc right parallel obj1 y; raw 2047 = signal not available (SNA)";
CM_ SG_ 606 PARK_pscRightParallelObj1Alpha "Parking assist sensors: psc right parallel obj1 alpha; raw 127 = signal not available (SNA)";
CM_ SG_ 606 PARK_pscRightParallelObj2Y "Parking assist sensors: psc right parallel obj2 y; raw 2047 = signal not available (SNA)";
CM_ SG_ 606 PARK_pscRightParallelObj2X "Parking assist sensors: psc right parallel obj2 x; raw 2047 = signal not available (SNA)";
CM_ SG_ 606 PARK_pscRightParallelObj2Alpha "Parking assist sensors: psc right parallel obj2 alpha; raw 127 = signal not available (SNA)";
CM_ SG_ 606 PARK_pscRightCrossObj1X "Parking assist sensors: psc right cross obj1 x; raw 2047 = signal not available (SNA)";
CM_ SG_ 606 PARK_pscRightCrossObj1Y "Parking assist sensors: psc right cross obj1 y; raw 2047 = signal not available (SNA)";
CM_ SG_ 606 PARK_pscRightCrossObj1Alpha "Parking assist sensors: psc right cross obj1 alpha; raw 127 = signal not available (SNA)";
CM_ SG_ 606 PARK_pscRightCrossObj2Y "Parking assist sensors: psc right cross obj2 y; raw 2047 = signal not available (SNA)";
CM_ SG_ 606 PARK_pscRightCrossObj2X "Parking assist sensors: psc right cross obj2 x; raw 2047 = signal not available (SNA)";
CM_ SG_ 606 PARK_pscRightCrossObj2Alpha "Parking assist sensors: psc right cross obj2 alpha; raw 127 = signal not available (SNA)";
CM_ BO_ 542 "Parking assist sensors message: psc status";
CM_ SG_ 542 PARK_pscParkStatus "Parking assist sensors: psc park status; raw 7 = signal not available (SNA)";
CM_ SG_ 542 PARK_pscParkAbortReason "Parking assist sensors: psc park abort reason; raw 31 = signal not available (SNA)";
CM_ SG_ 542 PARK_pscParallelSpace "The existence and type of a parallel parking slot identified by the ultrasonics.";
CM_ SG_ 542 PARK_pscCrossSpace "The type and existence of perpendicular parking slot identified through the ultrasonics";
CM_ SG_ 542 PARK_pscParallelRightParkable "Whether or not there is a valid path into a parallel parking slot on the right; raw 3 = signal not available (SNA)";
CM_ SG_ 542 PARK_pscParallelLeftParkable "Whether or not there is a valid path into a parallel parking slot on the left; raw 3 = signal not available (SNA)";
CM_ SG_ 542 PARK_pscCrossRightParkable "Parking assist sensors: psc cross right parkable; raw 3 = signal not available (SNA)";
CM_ SG_ 542 PARK_pscMaxVelocity "Parking assist sensors: psc max velocity; raw 63 = signal not available (SNA)";
CM_ SG_ 542 PARK_pscCrossLeftParkable "Parking assist sensors: psc cross left parkable; raw 3 = signal not available (SNA)";
CM_ SG_ 542 PARK_pscParkInstruction "The control request from PARK ECU during autopark manuever; raw 7 = signal not available (SNA)";
CM_ SG_ 542 PARK_pscManeuverDistance "Real time updated path length from center of vehicle reference frame to desired center of vehicle at end of current parking manuever; raw 2047 = signal not available (SNA)";
CM_ SG_ 542 PARK_pscAngleActive "Parking assist sensors: psc angle active";
CM_ SG_ 542 PARK_pscAngleRequest "Parking assist sensors: psc angle request";
CM_ SG_ 542 PARK_pscStatusCounter "Parking assist sensors: psc status counter";
CM_ SG_ 542 PARK_pscStatusChecksum "Parking assist sensors: psc status checksum";
CM_ BO_ 590 "Parking assist sensors message: psc veh slot";
CM_ SG_ 590 PARK_pscVehSlotType "Parking assist sensors: psc veh slot type";
CM_ SG_ 590 PARK_pscLeftParallelVehX "Parking assist sensors: psc left parallel veh x; raw 2047 = signal not available (SNA)";
CM_ SG_ 590 PARK_pscLeftParallelVehY "Parking assist sensors: psc left parallel veh y; raw 2047 = signal not available (SNA)";
CM_ SG_ 590 PARK_pscLeftParallelPsi "Parking assist sensors: psc left parallel psi; raw 8191 = signal not available (SNA)";
CM_ SG_ 590 PARK_pscLeftParallelSizeX "Parking assist sensors: psc left parallel size x; raw 255 = signal not available (SNA)";
CM_ SG_ 590 PARK_pscLeftParallelSizeY "Parking assist sensors: psc left parallel size y; raw 255 = signal not available (SNA)";
CM_ SG_ 590 PARK_pscLeftCrossVehX "Parking assist sensors: psc left cross veh x; raw 2047 = signal not available (SNA)";
CM_ SG_ 590 PARK_pscLeftCrossVehY "Parking assist sensors: psc left cross veh y; raw 2047 = signal not available (SNA)";
CM_ SG_ 590 PARK_pscLeftCrossPsi "Parking assist sensors: psc left cross psi; raw 8191 = signal not available (SNA)";
CM_ SG_ 590 PARK_pscLeftCrossSizeX "Parking assist sensors: psc left cross size x; raw 255 = signal not available (SNA)";
CM_ SG_ 590 PARK_pscLeftCrossSizeY "Parking assist sensors: psc left cross size y; raw 255 = signal not available (SNA)";
CM_ SG_ 590 PARK_pscRightParallelVehX "Parking assist sensors: psc right parallel veh x; raw 2047 = signal not available (SNA)";
CM_ SG_ 590 PARK_pscRightParallelVehY "Parking assist sensors: psc right parallel veh y; raw 2047 = signal not available (SNA)";
CM_ SG_ 590 PARK_pscRightParallelPsi "Parking assist sensors: psc right parallel psi; raw 8191 = signal not available (SNA)";
CM_ SG_ 590 PARK_pscRightParallelSizeX "Parking assist sensors: psc right parallel size x; raw 255 = signal not available (SNA)";
CM_ SG_ 590 PARK_pscRightParallelSizeY "Parking assist sensors: psc right parallel size y; raw 255 = signal not available (SNA)";
CM_ SG_ 590 PARK_pscRightCrossVehX "Parking assist sensors: psc right cross veh x; raw 2047 = signal not available (SNA)";
CM_ SG_ 590 PARK_pscRightCrossVehY "Parking assist sensors: psc right cross veh y; raw 2047 = signal not available (SNA)";
CM_ SG_ 590 PARK_pscRightCrossPsi "Parking assist sensors: psc right cross psi; raw 8191 = signal not available (SNA)";
CM_ SG_ 590 PARK_pscRightCrossSizeX "Parking assist sensors: psc right cross size x; raw 255 = signal not available (SNA)";
CM_ SG_ 590 PARK_pscRightCrossSizeY "Parking assist sensors: psc right cross size y; raw 255 = signal not available (SNA)";
CM_ BO_ 526 "Parking assist sensors message: sdi front";
CM_ SG_ 526 PARK_sdiSensor1RawDistData "Parking assist sensors: sdi sensor1 raw dist data; raw 511 = signal not available (SNA)";
CM_ SG_ 526 PARK_sdiSensor2RawDistData "Parking assist sensors: sdi sensor2 raw dist data; raw 511 = signal not available (SNA)";
CM_ SG_ 526 PARK_sdiSensor3RawDistData "Parking assist sensors: sdi sensor3 raw dist data; raw 511 = signal not available (SNA)";
CM_ SG_ 526 PARK_sdiSensor4RawDistData "Parking assist sensors: sdi sensor4 raw dist data; raw 511 = signal not available (SNA)";
CM_ SG_ 526 PARK_sdiSensor5RawDistData "Parking assist sensors: sdi sensor5 raw dist data; raw 511 = signal not available (SNA)";
CM_ SG_ 526 PARK_sdiSensor6RawDistData "Parking assist sensors: sdi sensor6 raw dist data; raw 511 = signal not available (SNA)";
CM_ SG_ 526 PARK_sdiFrontCounter "Parking assist sensors: sdi front counter";
CM_ SG_ 526 PARK_sdiFrontChecksum "Parking assist sensors: sdi front checksum";
CM_ BO_ 558 "Parking assist sensors message: sdi rear";
CM_ SG_ 558 PARK_sdiSensor7RawDistData "Parking assist sensors: sdi sensor7 raw dist data; raw 511 = signal not available (SNA)";
CM_ SG_ 558 PARK_sdiSensor8RawDistData "Parking assist sensors: sdi sensor8 raw dist data; raw 511 = signal not available (SNA)";
CM_ SG_ 558 PARK_sdiSensor9RawDistData "Parking assist sensors: sdi sensor9 raw dist data; raw 511 = signal not available (SNA)";
CM_ SG_ 558 PARK_sdiSensor10RawDistData "Parking assist sensors: sdi sensor10 raw dist data; raw 511 = signal not available (SNA)";
CM_ SG_ 558 PARK_sdiSensor11RawDistData "Parking assist sensors: sdi sensor11 raw dist data; raw 511 = signal not available (SNA)";
CM_ SG_ 558 PARK_sdiSensor12RawDistData "Parking assist sensors: sdi sensor12 raw dist data; raw 511 = signal not available (SNA)";
CM_ SG_ 558 PARK_sdiRearCounter "Parking assist sensors: sdi rear counter";
CM_ SG_ 558 PARK_sdiRearChecksum "Parking assist sensors: sdi rear checksum";
CM_ BO_ 814 "Parking assist sensors message: sensor status front";
CM_ SG_ 814 PARK_frontRightSensorState "Reports the state of the front right ultrasonic sensor; raw 3 = signal not available (SNA)";
CM_ SG_ 814 PARK_frontRightMiddleSensorState "Reports the state of the front right middle ultrasonic sensor; raw 3 = signal not available (SNA)";
CM_ SG_ 814 PARK_frontLeftMiddleSensorState "Reports the state of the front left middle ultrasonic sensor; raw 3 = signal not available (SNA)";
CM_ SG_ 814 PARK_frontLeftSensorState "Reports the state of the front left ultrasonic sensor; raw 3 = signal not available (SNA)";
CM_ SG_ 814 PARK_frontLeftRawDistData "Zone defined as -90 degrees -> -38 degrees, distance to object in units of centimeters; raw 255 = signal not available (SNA)";
CM_ SG_ 814 PARK_frontRightRawDistData "Zone defined as +38 degrees -> +90 degrees, distance to object in units of centimeters; raw 255 = signal not available (SNA)";
CM_ SG_ 814 PARK_systemStatusFront "Parking assist sensors: system status front; raw 3 = signal not available (SNA)";
CM_ SG_ 814 PARK_frontDtcPresent "Parking assist sensors: front dtc present; raw 3 = signal not available (SNA)";
CM_ SG_ 814 PARK_sensorStatusFrontCounter "Parking assist sensors: sensor status front counter";
CM_ SG_ 814 PARK_sensorStatusFrontChecksum "Parking assist sensors: sensor status front checksum";
CM_ BO_ 830 "Parking assist sensors message: sensor status rear";
CM_ SG_ 830 PARK_rearRightSensorState "Reports the state of the rear right ultrasonic sensor; raw 3 = signal not available (SNA)";
CM_ SG_ 830 PARK_rearRightMiddleSensorState "Reports the state of the rear right middle ultrasonic sensor; raw 3 = signal not available (SNA)";
CM_ SG_ 830 PARK_rearLeftMiddleSensorState "Reports the state of the rear left middle ultrasonic sensor; raw 3 = signal not available (SNA)";
CM_ SG_ 830 PARK_rearLeftSensorState "Reports the state of the rear left ultrasonic sensor; raw 3 = signal not available (SNA)";
CM_ SG_ 830 PARK_rearLeftRawDistData "Zone defined as -90 degrees to -125 degrees, distance to object in units of centimeters; raw 255 = signal not available (SNA)";
CM_ SG_ 830 PARK_rearRightRawDistData "Zone defined as +125 degrees to +90 degrees, distance to object in units of centimeters; raw 255 = signal not available (SNA)";
CM_ SG_ 830 PARK_systemStatusRear "Parking assist sensors: system status rear; raw 3 = signal not available (SNA)";
CM_ SG_ 830 PARK_rearDtcPresent "Parking assist sensors: rear dtc present; raw 3 = signal not available (SNA)";
CM_ SG_ 830 PARK_sensorStatusRearCounter "Parking assist sensors: sensor status rear counter";
CM_ SG_ 830 PARK_sensorStatusRearChecksum "Parking assist sensors: sensor status rear checksum";
CM_ BO_ 798 "Parking assist sensors message: status";
CM_ SG_ 798 PARK_status "Indicates status of park assist function; raw 3 = signal not available (SNA)";
CM_ SG_ 798 PARK_serviceRequest "Indicates whether or not PARK sensors/ECU require service; raw 3 = signal not available (SNA)";
CM_ SG_ 798 PARK_systemDtcPresent "Boolean indicating whether or not there is a DTC present; raw 3 = signal not available (SNA)";
CM_ SG_ 798 PARK_statusCounter "Parking assist sensors: status counter";
CM_ SG_ 798 PARK_statusChecksum "Parking assist sensors: status checksum";
CM_ SG_ 798 PARK_majorVersion "Parking assist sensors: major version; raw 255 = signal not available (SNA)";
CM_ SG_ 798 PARK_minorVersion "Parking assist sensors: minor version; raw 255 = signal not available (SNA)";
CM_ SG_ 798 PARK_subMinorVersion "Parking assist sensors: sub minor version; raw 255 = signal not available (SNA)";
CM_ BO_ 782 "Parking assist sensors message: status2";
CM_ SG_ 782 PARK_frontSVACharID "Parking assist sensors: front SVA char ID";
CM_ SG_ 782 PARK_pscRightCurbType "The type of curb for the parallel parking slot on the right side.";
CM_ SG_ 782 PARK_rearSVACharID "Parking assist sensors: rear SVA char ID";
CM_ SG_ 782 PARK_pscLeftCurbType "The type of curb identified for a parallel parking space on the left.";
CM_ SG_ 782 PARK_autoCalComplete "Parking assist sensors: auto cal complete";
CM_ SG_ 782 PARK_geometryType "Parking assist sensors: geometry type";
CM_ SG_ 782 PARK_tireFitment "Parking assist sensors: tire fitment; raw 3 = signal not available (SNA)";
CM_ SG_ 782 PARK_rackDetected "Parking assist sensors: rack detected; raw 3 = signal not available (SNA)";
CM_ SG_ 782 PARK_sdiActive "Whether or not the raw sensor measurements from the ultrasonics are present and valid";
CM_ SG_ 782 PARK_sdiNoise "The output of the noise detection algorithm for raw sensor measurements, indicates if the measurements are degraded due to ambient noise; raw 3 = signal not available (SNA)";
CM_ SG_ 782 PARK_sdiBlindSpotRight "The output of the PARK ECU blindspot algorithm on the right side of the car, indicates the presence of a vehicle; raw 3 = signal not available (SNA)";
CM_ SG_ 782 PARK_sdiBlindSpotLeft "The output of the PARK ECU blindspot algorithm on the left side of the car, indicates the presence of a vehicle; raw 3 = signal not available (SNA)";
CM_ SG_ 782 PARK_sensorType "Parking assist sensors: sensor type; raw 3 = signal not available (SNA)";
CM_ SG_ 782 PARK_status2Counter "Parking assist sensors: status2 counter";
CM_ SG_ 782 PARK_status2Checksum "Parking assist sensors: status2 checksum";
CM_ BO_ 1329 "Radar message: info";
CM_ SG_ 1329 RADC_infoIndex "Radar: info index";
CM_ SG_ 1329 RADC_infoBuildType "Radar: info build type";
CM_ SG_ 1329 RADC_infoBuildConfigID "Radar: info build config ID";
CM_ SG_ 1329 RADC_infoHardwareID "Radar: info hardware ID";
CM_ SG_ 1329 RADC_infoComponentID "Radar: info component ID";
CM_ SG_ 1329 RADC_infoPcbaID "Radar: info pcba ID";
CM_ SG_ 1329 RADC_infoAssemblyID "Radar: info assembly ID";
CM_ SG_ 1329 RADC_infoUsageID "Radar: info usage ID";
CM_ SG_ 1329 RADC_infoSubUsageID "Radar: info sub usage ID";
CM_ SG_ 1329 RADC_infoApplicationCRC "Radar: info application CRC";
CM_ SG_ 1329 RADC_infoPlatformType "Radar: info platform type";
CM_ SG_ 1329 RADC_infoMajorVersion "Radar: info major version";
CM_ SG_ 1329 RADC_infoBranchOrigin "Radar: info branch origin";
CM_ SG_ 1329 RADC_infoMaturity "Radar: info maturity";
CM_ SG_ 1329 RADC_infoHardwareRevision "Radar: info hardware revision";
CM_ SG_ 1329 RADC_infoBootUdsProtoVersion "Radar: info boot uds proto version";
CM_ SG_ 1329 RADC_infoBootloaderCRC "Radar: info bootloader CRC";
CM_ BO_ 257 "Restraint control module message: inertial1";
CM_ SG_ 257 RCM_yawRate "Offset compensated yaw rate measured by the airbag ECU. ISO axis convention (Positive during left turn); raw 32768 = signal not available (SNA)";
CM_ SG_ 257 RCM_pitchRate "Offset compensated pitch rate measured by the airbag ECU. ISO axis convention (positive when the nose pitches down); raw 16384 = signal not available (SNA)";
CM_ SG_ 257 RCM_rollRate "Offset compensated roll rate measured by the airbag ECU. ISO axis convention (positive during left turn); raw 16384 = signal not available (SNA)";
CM_ SG_ 257 RCM_rollRateQF "Restraint control module: roll rate QF";
CM_ SG_ 257 RCM_yawRateQF "Restraint control module: yaw rate QF";
CM_ SG_ 257 RCM_pitchRateQF "Restraint control module: pitch rate QF";
CM_ SG_ 257 RCM_inertial1Counter "Restraint control module: inertial1 counter";
CM_ SG_ 257 RCM_inertial1Checksum "Restraint control module: inertial1 checksum";
CM_ BO_ 273 "Restraint control module message: inertial2";
CM_ SG_ 273 RCM_longitudinalAccel "Offset compensated longitudinal acceleration measured by the airbag ECU. ISO axis convention (positive during forward acceleration); raw 32768 = signal not available (SNA)";
CM_ SG_ 273 RCM_lateralAccel "Reports offset compensated lateral acceleration measured by the airbag ECU. Follows ISO axis convention that measurements are positive during left turns and negative during right turns; raw 32768 = signal not available (SNA)";
CM_ SG_ 273 RCM_verticalAccel "Offset compensated vertical acceleration measured by the airbag ECU. ISO axis convention (positive up); raw 32768 = signal not available (SNA)";
CM_ SG_ 273 RCM_longitudinalAccelQF "Restraint control module: longitudinal accel QF";
CM_ SG_ 273 RCM_lateralAccelQF "Restraint control module: lateral accel QF";
CM_ SG_ 273 RCM_verticalAccelQF "Restraint control module: vertical accel QF";
CM_ SG_ 273 RCM_CGTranslationFault "Restraint control module: CG translation fault";
CM_ SG_ 273 RCM_inertial2Counter "Restraint control module: inertial2 counter";
CM_ SG_ 273 RCM_inertial2Checksum "Restraint control module: inertial2 checksum";
CM_ BO_ 849 "Restraint control module message: info";
CM_ SG_ 849 RCM_infoIndex "Restraint control module: info index";
CM_ SG_ 849 RCM_infoBuildType "Restraint control module: info build type";
CM_ SG_ 849 RCM_infoComponentID "Restraint control module: info component ID";
CM_ SG_ 849 RCM_infoPcbaID "Reports the Restraint Control Module (RCM) Printed Circuit Board Assembly (PCBA) identifier.";
CM_ SG_ 849 RCM_infoAssemblyID "Restraint control module: info assembly ID";
CM_ SG_ 849 RCM_infoUsageID "Reports the Restraint Control Module (RCM) usage identification.";
CM_ SG_ 849 RCM_infoApplicationCRC "Reports the Restraint Control Module (RCM) application Cyclic Redundancy Check (CRC).";
CM_ SG_ 849 RCM_infoBootUdsProtoVersion "Reports the Restraint Control Module (RCM) boot Unified Diagnostic Services (UDS) protocol version.";
CM_ SG_ 849 RCM_infoBootloaderCRC "Reports the Restraint Control Module (RCM) bootloader Cyclic Redundancy Check (CRC).";
CM_ SG_ 849 RCM_infoAlgoCalID "Reports the Restraint Control Module (RCM) algorithm calibration identification.";
CM_ SG_ 849 RCM_infoVariantCRC "Reports the Restraint Control Module (RCM) variant Cyclic Redundancy Check (CRC).";
CM_ BO_ 529 "Restraint control module message: status";
CM_ SG_ 529 RCM_statusChecksum "Restraint control module: status checksum";
CM_ SG_ 529 RCM_statusCounter "Restraint control module: status counter";
CM_ SG_ 529 RCM_armStatus "Reports the arm status of the Restraint Control Module (RCM); raw 3 = signal not available (SNA)";
CM_ SG_ 529 RCM_warningIndicatorState "Reports whether the Restraint Control Module (RCM) warning indicator is present on the User Interface (UI); raw 3 = signal not available (SNA)";
CM_ SG_ 529 RCM_passAirbagIndicatorRequest "Reports status of the Front Passenger Airbag Off telltale; raw 3 = signal not available (SNA)";
CM_ SG_ 529 RCM_airbagCutoffStatus "Reports the front passenger airbag enabled or disabled status; raw 3 = signal not available (SNA)";
CM_ SG_ 529 RCM_alrSwitchStatus "Reports status of the front passenger automatic locking seat belt retractor; raw 3 = signal not available (SNA)";
CM_ SG_ 529 RCM_vinLearnFlag "Reports whether the Vehicle Identification Number has been learned; raw 3 = signal not available (SNA)";
CM_ SG_ 529 RCM_seatTrackPositionDrvr "Driver seat track position status; raw 3 = signal not available (SNA)";
CM_ SG_ 529 RCM_seatTrackPositionPass "Passenger seat track position status; raw 3 = signal not available (SNA)";
CM_ SG_ 529 RCM_edr1State "Reports status of Restraint Control Module (RCM) Event Data Recorder (EDR) memory slot 1.";
CM_ SG_ 529 RCM_edr2State "Reports status of Restraint Control Module (RCM) Event Data Recorder (EDR) memory slot 2.";
CM_ SG_ 529 RCM_keepPowerReason "Restraint Control Module request to maintain power; raw 8 = signal not available (SNA)";
CM_ SG_ 529 RCM_imuOffsetLearnState "Restraint control module: imu offset learn state";
CM_ SG_ 529 RCM_edr3State "Reports status of Restraint Control Module (RCM) Event Data Recorder (EDR) memory slot 3.";
CM_ SG_ 529 RCM_driverOrientationInitStatus "Restraint control module: driver orientation init status; raw 7 = signal not available (SNA)";
CM_ SG_ 529 RCM_occupantClassificationSource "Indicates whether the occupant classification source is the Right Vehicle Controller (VCRIGHT) or the Occupancy Classification System - 1st Row Passenger (OCS1P).";
CM_ SG_ 529 RCM_pedProEDR1State "Reports status of the PedPro Event Data Recorder (EDR) memory slot 1.";
CM_ SG_ 529 RCM_pedProEDR2State "Reports status of the PedPro Event Data Recorder (EDR) memory slot 2.";
CM_ BO_ 879 "Tire pressure monitoring message: status c";
CM_ SG_ 879 TPMS_c_globalHardWarning "Tire pressure monitoring: c global hard warning";
CM_ SG_ 879 TPMS_c_globalSoftWarning "Tire pressure monitoring: c global soft warning";
CM_ SG_ 879 TPMS_systemMalfunction "Tire pressure monitoring: system malfunction";
CM_ SG_ 879 TPMS_WA_version "Tire pressure monitoring: WA version";
CM_ SG_ 879 TPMS_globalDeltaPressure "Tire pressure monitoring: global delta pressure";
CM_ SG_ 879 TPMS_newSensorLearnt "Tire pressure monitoring: new sensor learnt";
CM_ SG_ 879 TPMS_softWarningRR "Tire pressure monitoring: soft warning RR";
CM_ SG_ 879 TPMS_hardWarningRR "Tire pressure monitoring: hard warning RR";
CM_ SG_ 879 TPMS_softWarningRL "Tire pressure monitoring: soft warning RL";
CM_ SG_ 879 TPMS_hardWarningRL "Tire pressure monitoring: hard warning RL";
CM_ SG_ 879 TPMS_softWarningFR "Tire pressure monitoring: soft warning FR";
CM_ SG_ 879 TPMS_hardWarningFR "Tire pressure monitoring: hard warning FR";
CM_ SG_ 879 TPMS_softWarningFL "Tire pressure monitoring: soft warning FL";
CM_ SG_ 879 TPMS_hardWarningFL "Tire pressure monitoring: hard warning FL";
CM_ SG_ 879 TPMS_learningStatus "Monitors Tire Pressure Monitoring System (TPMS) Learn Status and evaluates issues.";
CM_ SG_ 879 TPMS_localisationStatus "Monitors Tire Pressure Monitoring System (TPMS) Localization Status and evaluates issues.";
CM_ SG_ 879 TPMS_deltaPressWarningFL "Tire pressure monitoring: delta press warning FL";
CM_ SG_ 879 TPMS_deltaPressWarningFR "Tire pressure monitoring: delta press warning FR";
CM_ SG_ 879 TPMS_deltaPressWarningRL "Tire pressure monitoring: delta press warning RL";
CM_ SG_ 879 TPMS_deltaPressWarningRR "Tire pressure monitoring: delta press warning RR";
CM_ SG_ 879 TPMS_sensorNoResponseFL "Count of times Front Left sensor did not respond to message";
CM_ SG_ 879 TPMS_sensorNoResponseFR "Count of times Front Right sensor did not respond to message";
CM_ SG_ 879 TPMS_sensorNoResponseRL "Count of times Rear Left sensor did not respond to message";
CM_ SG_ 879 TPMS_sensorNoResponseRR "Count of times Rear Right sensor did not respond to message";
CM_ SG_ 879 TPMS_sensorThermShutdownFL "Tire pressure monitoring: sensor therm shutdown FL";
CM_ SG_ 879 TPMS_sensorThermShutdownFR "Tire pressure monitoring: sensor therm shutdown FR";
CM_ SG_ 879 TPMS_sensorThermShutdownRL "Tire pressure monitoring: sensor therm shutdown RL";
CM_ SG_ 879 TPMS_sensorThermShutdownRR "Tire pressure monitoring: sensor therm shutdown RR";
CM_ SG_ 879 TPMS_sensorBatteryLowFL "Tracks near end of life sensor batteries in the fleet.";
CM_ SG_ 879 TPMS_sensorBatteryLowFR "Tracks near end of life sensor batteries in the fleet.";
CM_ SG_ 879 TPMS_sensorBatteryLowRL "Tracks near end of life sensor batteries in the fleet.";
CM_ SG_ 879 TPMS_sensorBatteryLowRR "Tracks near end of life sensor batteries in the fleet.";
CM_ SG_ 879 TPMS_sensorDefectiveFL "Tracks malfunctioning sensors in the fleet.";
CM_ SG_ 879 TPMS_sensorDefectiveFR "Tracks malfunctioning sensors in the fleet.";
CM_ SG_ 879 TPMS_sensorDefectiveRL "Tracks malfunctioning sensors in the fleet.";
CM_ SG_ 879 TPMS_sensorDefectiveRR "Tracks malfunctioning sensors in the fleet.";
CM_ SG_ 879 TPMS_ecuUnderVoltage "Tire pressure monitoring: ecu under voltage";
CM_ SG_ 879 TPMS_ecuOverVoltage "Tire pressure monitoring: ecu over voltage";
CM_ SG_ 879 TPMS_ecuRamRomNvMFail "Tire pressure monitoring: ecu ram rom nv m fail";
CM_ SG_ 879 TPMS_rfReceiverFail "Tire pressure monitoring: rf receiver fail";
CM_ SG_ 879 TPMS_wheelPulseMissing "Tire pressure monitoring: wheel pulse missing";
CM_ SG_ 879 TPMS_vehicleSpeedFail "Tire pressure monitoring: vehicle speed fail";
CM_ SG_ 879 TPMS_externalTemperatureFail "Tire pressure monitoring: external temperature fail";
CM_ SG_ 879 TPMS_eolNotCompleted "Monitors sensor completion of End of Line (EOL) routine.";
CM_ SG_ 879 TPMS_rcpFront "Front tire recommended cold pressure";
CM_ SG_ 879 TPMS_rcpRear "Rear tire recommended cold pressure";
CM_ BO_ 799 "Tire pressure monitoring message: data";
CM_ SG_ 799 TPMS_pressureFL "front left tire pressure; raw 255 = signal not available (SNA)";
CM_ SG_ 799 TPMS_temperatureFL "front left tire temperature; raw 255 = signal not available (SNA)";
CM_ SG_ 799 TPMS_pressureFR "front right tire pressure; raw 255 = signal not available (SNA)";
CM_ SG_ 799 TPMS_temperatureFR "front right tire temperature; raw 255 = signal not available (SNA)";
CM_ SG_ 799 TPMS_pressureRL "rear left tire pressure; raw 255 = signal not available (SNA)";
CM_ SG_ 799 TPMS_temperatureRL "rear left tire temperature; raw 255 = signal not available (SNA)";
CM_ SG_ 799 TPMS_pressureRR "rear right tire pressure; raw 255 = signal not available (SNA)";
CM_ SG_ 799 TPMS_temperatureRR "rear right tire temperature; raw 255 = signal not available (SNA)";
CM_ BO_ 1519 "Tire pressure monitoring message: info";
CM_ SG_ 1519 TPMS_infoIndex "Tire pressure monitoring: info index";
CM_ SG_ 1519 TPMS_infoComponentID "Tire pressure monitoring: info component ID";
CM_ SG_ 1519 TPMS_infoPcbaID "Tire pressure monitoring: info pcba ID";
CM_ SG_ 1519 TPMS_infoAssemblyID "Tire pressure monitoring: info assembly ID";
CM_ SG_ 1519 TPMS_infoUsageID "Tire pressure monitoring: info usage ID";
CM_ SG_ 1519 TPMS_infoApplicationCRC "Tire pressure monitoring: info application CRC";
CM_ SG_ 1519 TPMS_infoBootUdsProtoVersion "Tire pressure monitoring: info boot uds proto version";
CM_ SG_ 1519 TPMS_infoBootloaderCRC "Tire pressure monitoring: info bootloader CRC";
CM_ BO_ 659 "Touchscreen user interface computer message: chassis control; forwarded onto this bus by the gateway";
CM_ SG_ 659 UI_steeringTuneRequest "UI customer level request for steering feel. MS had comfort, normal, sport. M3 intent is Normal, sport see SW-95934";
CM_ SG_ 659 UI_tractionControlMode "Transport user selected traction control modes";
CM_ SG_ 659 UI_parkBrakeRequest "User selection for Park brake; raw 3 = signal not available (SNA)";
CM_ SG_ 659 UI_winchModeRequest "Winch mode (towing) request";
CM_ SG_ 659 UI_trailerMode "Indicates whether trailer mode is selected. To be used when towing a trailer.";
CM_ SG_ 659 UI_accOvertakeEnable "Enable ACC Overtake assistance (reduce follow distance when the turn signal is on), UI firmware only sets datavalue to True; raw 3 = signal not available (SNA)";
CM_ SG_ 659 UI_aebEnable "Enable Autonomous Emergency Brakes; raw 3 = signal not available (SNA)";
CM_ SG_ 659 UI_aesEnable "Enable Automatic Emergency Steering (associated datavalue set to true and never changed by UI firmware); raw 3 = signal not available (SNA)";
CM_ SG_ 659 UI_ahlbEnable "Enable Automatic High/Low Beams; raw 3 = signal not available (SNA)";
CM_ SG_ 659 UI_autoLaneChangeEnable "Enable Automatic Lane Change; raw 3 = signal not available (SNA)";
CM_ SG_ 659 UI_winchProxUserOverride "User feedback from tow mode panel confirming that charge cable is disconnected when vehicle is unable to determine cable status";
CM_ SG_ 659 UI_autoParkRequest "Request Automatic Parking; raw 15 = signal not available (SNA)";
CM_ SG_ 659 UI_bsdEnable "Enable Blind Spot Detection (datavalue defaults to true and not changed by UI firmware); raw 3 = signal not available (SNA)";
CM_ SG_ 659 UI_fcwEnable "Enable Forward Collision Warning; raw 3 = signal not available (SNA)";
CM_ SG_ 659 UI_fcwSensitivity "Forward Collision Warning Level; raw 3 = signal not available (SNA)";
CM_ SG_ 659 UI_latControlEnable "Enable Lateral Control (lane centering, lane keeping, lane changing); raw 3 = signal not available (SNA)";
CM_ SG_ 659 UI_ldwEnable "Enable Lane Departure Warning; raw 3 = signal not available (SNA)";
CM_ BO_ 1016 "Touchscreen user interface computer message: driver assist control; forwarded onto this bus by the gateway";
CM_ SG_ 1016 UI_ulcStalkConfirm "Drive on autopilot stalk confirmation mode (set by feature config).";
CM_ SG_ 1016 UI_lssLkaEnabled "User setting for lane keep assist";
CM_ SG_ 1016 UI_lssLdwEnabled "User setting for lane departure warning";
CM_ SG_ 1016 UI_driveOnMapsEnable "Drive on Autopilot enabled";
CM_ SG_ 1016 UI_lssElkEnabled "User setting for emergency lane keep";
CM_ SG_ 1016 UI_selfParkRequest "Self park request; raw 15 = signal not available (SNA)";
CM_ SG_ 1016 UI_followNavRouteEnable "Following route with Drive on Autopilot";
CM_ SG_ 1016 UI_ulcSpeedConfig "Drive on autopilot speed base lane changes mode.";
CM_ SG_ 1016 UI_suppressExitPassingLane "Navigate on Autopilot will not suggest lane changes out of the passing lane";
CM_ SG_ 1016 UI_smartSummonType "Type of smart summon session (Find Me, Pin Drop, Smart Autopark)";
CM_ SG_ 1016 UI_isaSpeedingChimeMuted "Reports the user input of Intelligent Speed Assist (ISA) speed chime alert option.";
CM_ BO_ 568 "Touchscreen user interface computer message: driver assist map data; forwarded onto this bus by the gateway";
CM_ SG_ 568 UI_roadClass "Autopilot map road class; raw 0 = signal not available (SNA)";
CM_ SG_ 568 UI_navRouteActive "Navigation route is active";
CM_ SG_ 568 UI_parallelAutoparkEnabled "Autopilot map parallel park enabled.";
CM_ SG_ 568 UI_perpendicularAutoparkEnabled "Autopilot map perpendicular park enabled.";
CM_ SG_ 568 UI_controlledAccess "DAS map controlled access segment.";
CM_ SG_ 568 UI_autosteerRestricted "Autopilot map is autostreer restricted.";
CM_ BO_ 760 "Touchscreen user interface computer message: gps vehicle speed; forwarded onto this bus by the gateway";
CM_ SG_ 760 UI_mapSpeedLimitUnits "Autopilot map speed limit units.";
CM_ SG_ 760 UI_mppSpeedLimit "Autopilot map speed limit";
CM_ SG_ 760 UI_gpsNmeaMIA "GPS NMEA data MIA";
CM_ SG_ 760 UI_gpsAntennaDisconnected "GPS antenna state";
CM_ SG_ 760 UI_conditionalLimitActive "Conditional speed limit condition is currently active";
CM_ SG_ 760 UI_conditionalSpeedLimit "Conditional speed limit value; raw 31 = signal not available (SNA)";
CM_ BO_ 1011 "Touchscreen user interface computer message: odo; forwarded onto this bus by the gateway";
CM_ SG_ 1011 UI_odometer "Odometer; raw 16777215 = signal not available (SNA)";
CM_ BO_ 723 "Touchscreen user interface computer message: solar data; forwarded onto this bus by the gateway";
CM_ SG_ 723 UI_isSunUp "is sun up; raw 3 = signal not available (SNA)";
CM_ SG_ 723 UI_solarElevationAngle "Solar Elevation Angle; raw 127 = signal not available (SNA)";
CM_ SG_ 723 UI_screenPCBTemperature "Temperature of display PCB";
CM_ SG_ 723 UI_minsToSunset "time until to sunset";
CM_ SG_ 723 UI_minsToSunrise "time until to sunrise";
CM_ BO_ 851 "Touchscreen user interface computer message: status; forwarded onto this bus by the gateway";
CM_ SG_ 851 UI_touchActive "No touchscreen errors";
CM_ SG_ 851 UI_audioActive "Audio system is ready.";
CM_ SG_ 851 UI_cellActive "Cell is powered";
CM_ SG_ 851 UI_displayReady "UI is ready (GUI_allReady) and display is ok (GUI_displayHardwareOK)";
CM_ SG_ 851 UI_displayOn "UI display on/off status";
CM_ SG_ 851 UI_wifiActive "WiFi active.";
CM_ SG_ 851 UI_wifiConnected "WiFi Connected.";
CM_ SG_ 851 UI_readyForDrive "Ready for drive (UI ready or self park request)";
CM_ SG_ 851 UI_cellConnected "Detects if the cell is connected to a network.";
CM_ SG_ 851 UI_vpnActive "VPN connected.";
CM_ SG_ 851 UI_factoryReset "UI request for factory reset; raw 0 = signal not available (SNA)";
CM_ SG_ 851 UI_gpsActive "GPS has valid fix";
CM_ SG_ 851 UI_cellNetworkTechnology "Describes the type of cellular network to which the car computer is connected: GPRS_2G(114Kbps) < EGDE_2G(368Kbps) < 3G(3Mbps) < HSDPA_3G(14Mbps) < HSPAplus_4Gg(168Mbps) < 4G_LTE(299Mbps); raw 15 = signal not available (SNA)";
CM_ SG_ 851 UI_falseTouchCounter "Count false touches after display is off.";
CM_ SG_ 851 UI_cellSignalBars "Number of cellular signal bars displayed on the UI, derived from cellSignalStrength; raw 7 = signal not available (SNA)";
CM_ SG_ 851 UI_trailerModeTelltale "Color of the trailer mode telltale";
CM_ SG_ 851 UI_pcbTemperature "PCB digital temp sensor reading in DegC";
CM_ SG_ 851 UI_cpuTemperature "Apollo Lake SOC temperature in DegC";
CM_ BO_ 807 "USM ECU message: info";
CM_ SG_ 807 USM_infoIndex "USM ECU: info index";
CM_ SG_ 807 USM_infoBuildType "USM ECU: info build type";
CM_ SG_ 807 USM_infoBuildConfigId "USM ECU: info build config id";
CM_ SG_ 807 USM_infoHardwareId "USM ECU: info hardware id";
CM_ SG_ 807 USM_infoComponentId "USM ECU: info component id";
CM_ SG_ 807 USM_infoPcbaId "USM ECU: info pcba id";
CM_ SG_ 807 USM_infoAssemblyId "USM ECU: info assembly id; raw 255 = signal not available (SNA)";
CM_ SG_ 807 USM_infoUsageId "USM ECU: info usage id";
CM_ SG_ 807 USM_infoSubUsageId "USM ECU: info sub usage id";
CM_ SG_ 807 USM_infoAppCrc "USM ECU: info app crc";
BA_DEF_ BO_ "GenMsgCycleTime" INT 0 3600000;
BA_DEF_ BO_ "GenMsgSendType" ENUM "Cyclic","NotUsed","NotUsed","NotUsed","NotUsed","NotUsed","NotUsed","IfActive","NoMsgSendType","NotUsed";
BA_DEF_ BO_ "VFrameFormat" ENUM "StandardCAN","ExtendedCAN","reserved","J1939PG","reserved","reserved","reserved","reserved","reserved","reserved","reserved","reserved","reserved","reserved","StandardCAN_FD","ExtendedCAN_FD";
BA_DEF_ BO_ "CANFD_BRS" ENUM "0","1";
BA_DEF_ SG_ "GenSigSNA" STRING;
BA_DEF_ SG_ "SystemSignalLongSymbol" STRING;
BA_DEF_ SG_ "Confidence" ENUM "validated","plausible","layout-only","contradicted";
BA_DEF_DEF_ "GenMsgCycleTime" 0;
BA_DEF_DEF_ "GenMsgSendType" "NoMsgSendType";
BA_DEF_DEF_ "VFrameFormat" "StandardCAN";
BA_DEF_DEF_ "CANFD_BRS" "1";
BA_DEF_DEF_ "GenSigSNA" "";
BA_DEF_DEF_ "SystemSignalLongSymbol" "";
BA_DEF_DEF_ "Confidence" "layout-only";
BA_ "GenMsgCycleTime" BO_ 606 100;
BA_ "GenMsgSendType" BO_ 606 0;
BA_ "GenMsgCycleTime" BO_ 542 40;
BA_ "GenMsgSendType" BO_ 542 0;
BA_ "GenMsgCycleTime" BO_ 590 100;
BA_ "GenMsgSendType" BO_ 590 0;
BA_ "GenMsgCycleTime" BO_ 526 40;
BA_ "GenMsgSendType" BO_ 526 0;
BA_ "GenMsgCycleTime" BO_ 558 40;
BA_ "GenMsgSendType" BO_ 558 0;
BA_ "GenMsgCycleTime" BO_ 814 100;
BA_ "GenMsgSendType" BO_ 814 0;
BA_ "GenMsgCycleTime" BO_ 830 100;
BA_ "GenMsgSendType" BO_ 830 0;
BA_ "GenMsgCycleTime" BO_ 798 500;
BA_ "GenMsgSendType" BO_ 798 0;
BA_ "GenMsgCycleTime" BO_ 782 250;
BA_ "GenMsgSendType" BO_ 782 0;
BA_ "GenMsgCycleTime" BO_ 1329 1000;
BA_ "GenMsgSendType" BO_ 1329 0;
BA_ "GenMsgCycleTime" BO_ 257 20;
BA_ "GenMsgSendType" BO_ 257 0;
BA_ "GenMsgCycleTime" BO_ 273 20;
BA_ "GenMsgSendType" BO_ 273 0;
BA_ "GenMsgCycleTime" BO_ 849 2000;
BA_ "GenMsgSendType" BO_ 849 0;
BA_ "GenMsgCycleTime" BO_ 529 100;
BA_ "GenMsgSendType" BO_ 529 0;
BA_ "GenMsgCycleTime" BO_ 879 1000;
BA_ "GenMsgSendType" BO_ 879 0;
BA_ "GenMsgCycleTime" BO_ 799 1000;
BA_ "GenMsgSendType" BO_ 799 0;
BA_ "GenMsgCycleTime" BO_ 1519 1000;
BA_ "GenMsgSendType" BO_ 1519 0;
BA_ "GenMsgCycleTime" BO_ 659 500;
BA_ "GenMsgSendType" BO_ 659 0;
BA_ "GenMsgCycleTime" BO_ 1016 1000;
BA_ "GenMsgSendType" BO_ 1016 0;
BA_ "GenMsgCycleTime" BO_ 568 500;
BA_ "GenMsgSendType" BO_ 568 0;
BA_ "GenMsgCycleTime" BO_ 760 1000;
BA_ "GenMsgSendType" BO_ 760 0;
BA_ "GenMsgCycleTime" BO_ 1011 1000;
BA_ "GenMsgSendType" BO_ 1011 0;
BA_ "GenMsgCycleTime" BO_ 723 1000;
BA_ "GenMsgSendType" BO_ 723 0;
BA_ "GenMsgCycleTime" BO_ 851 1000;
BA_ "GenMsgSendType" BO_ 851 0;
BA_ "GenMsgCycleTime" BO_ 807 1000;
BA_ "GenMsgSendType" BO_ 807 0;
BA_ "Confidence" SG_ 606 PARK_pscEnvSlotType 1;
BA_ "Confidence" SG_ 606 PARK_pscLeftParallelObj1X 0;
BA_ "GenSigSNA" SG_ 606 PARK_pscLeftParallelObj1X "2047";
BA_ "Confidence" SG_ 606 PARK_pscLeftParallelObj1Y 0;
BA_ "GenSigSNA" SG_ 606 PARK_pscLeftParallelObj1Y "2047";
BA_ "Confidence" SG_ 606 PARK_pscLeftParallelObj1Alpha 0;
BA_ "GenSigSNA" SG_ 606 PARK_pscLeftParallelObj1Alpha "127";
BA_ "Confidence" SG_ 606 PARK_pscLeftParallelObj2Y 0;
BA_ "GenSigSNA" SG_ 606 PARK_pscLeftParallelObj2Y "2047";
BA_ "Confidence" SG_ 606 PARK_pscLeftParallelObj2X 0;
BA_ "GenSigSNA" SG_ 606 PARK_pscLeftParallelObj2X "2047";
BA_ "Confidence" SG_ 606 PARK_pscLeftParallelObj2Alpha 0;
BA_ "GenSigSNA" SG_ 606 PARK_pscLeftParallelObj2Alpha "127";
BA_ "Confidence" SG_ 606 PARK_pscLeftCrossObj1X 0;
BA_ "GenSigSNA" SG_ 606 PARK_pscLeftCrossObj1X "2047";
BA_ "Confidence" SG_ 606 PARK_pscLeftCrossObj1Y 0;
BA_ "GenSigSNA" SG_ 606 PARK_pscLeftCrossObj1Y "2047";
BA_ "Confidence" SG_ 606 PARK_pscLeftCrossObj1Alpha 0;
BA_ "GenSigSNA" SG_ 606 PARK_pscLeftCrossObj1Alpha "127";
BA_ "Confidence" SG_ 606 PARK_pscLeftCrossObj2Y 0;
BA_ "GenSigSNA" SG_ 606 PARK_pscLeftCrossObj2Y "2047";
BA_ "Confidence" SG_ 606 PARK_pscLeftCrossObj2X 0;
BA_ "GenSigSNA" SG_ 606 PARK_pscLeftCrossObj2X "2047";
BA_ "Confidence" SG_ 606 PARK_pscLeftCrossObj2Alpha 0;
BA_ "GenSigSNA" SG_ 606 PARK_pscLeftCrossObj2Alpha "127";
BA_ "Confidence" SG_ 606 PARK_pscRightParallelObj1X 0;
BA_ "GenSigSNA" SG_ 606 PARK_pscRightParallelObj1X "2047";
BA_ "Confidence" SG_ 606 PARK_pscRightParallelObj1Y 0;
BA_ "GenSigSNA" SG_ 606 PARK_pscRightParallelObj1Y "2047";
BA_ "Confidence" SG_ 606 PARK_pscRightParallelObj1Alpha 0;
BA_ "GenSigSNA" SG_ 606 PARK_pscRightParallelObj1Alpha "127";
BA_ "Confidence" SG_ 606 PARK_pscRightParallelObj2Y 0;
BA_ "GenSigSNA" SG_ 606 PARK_pscRightParallelObj2Y "2047";
BA_ "Confidence" SG_ 606 PARK_pscRightParallelObj2X 0;
BA_ "GenSigSNA" SG_ 606 PARK_pscRightParallelObj2X "2047";
BA_ "Confidence" SG_ 606 PARK_pscRightParallelObj2Alpha 0;
BA_ "GenSigSNA" SG_ 606 PARK_pscRightParallelObj2Alpha "127";
BA_ "Confidence" SG_ 606 PARK_pscRightCrossObj1X 0;
BA_ "GenSigSNA" SG_ 606 PARK_pscRightCrossObj1X "2047";
BA_ "Confidence" SG_ 606 PARK_pscRightCrossObj1Y 0;
BA_ "GenSigSNA" SG_ 606 PARK_pscRightCrossObj1Y "2047";
BA_ "Confidence" SG_ 606 PARK_pscRightCrossObj1Alpha 0;
BA_ "GenSigSNA" SG_ 606 PARK_pscRightCrossObj1Alpha "127";
BA_ "Confidence" SG_ 606 PARK_pscRightCrossObj2Y 0;
BA_ "GenSigSNA" SG_ 606 PARK_pscRightCrossObj2Y "2047";
BA_ "Confidence" SG_ 606 PARK_pscRightCrossObj2X 0;
BA_ "GenSigSNA" SG_ 606 PARK_pscRightCrossObj2X "2047";
BA_ "Confidence" SG_ 606 PARK_pscRightCrossObj2Alpha 0;
BA_ "GenSigSNA" SG_ 606 PARK_pscRightCrossObj2Alpha "127";
BA_ "Confidence" SG_ 542 PARK_pscParkStatus 0;
BA_ "GenSigSNA" SG_ 542 PARK_pscParkStatus "7";
BA_ "Confidence" SG_ 542 PARK_pscParkAbortReason 0;
BA_ "GenSigSNA" SG_ 542 PARK_pscParkAbortReason "31";
BA_ "Confidence" SG_ 542 PARK_pscParallelSpace 0;
BA_ "Confidence" SG_ 542 PARK_pscCrossSpace 0;
BA_ "Confidence" SG_ 542 PARK_pscParallelRightParkable 0;
BA_ "GenSigSNA" SG_ 542 PARK_pscParallelRightParkable "3";
BA_ "Confidence" SG_ 542 PARK_pscParallelLeftParkable 0;
BA_ "GenSigSNA" SG_ 542 PARK_pscParallelLeftParkable "3";
BA_ "Confidence" SG_ 542 PARK_pscCrossRightParkable 0;
BA_ "GenSigSNA" SG_ 542 PARK_pscCrossRightParkable "3";
BA_ "Confidence" SG_ 542 PARK_pscMaxVelocity 0;
BA_ "GenSigSNA" SG_ 542 PARK_pscMaxVelocity "63";
BA_ "Confidence" SG_ 542 PARK_pscCrossLeftParkable 0;
BA_ "GenSigSNA" SG_ 542 PARK_pscCrossLeftParkable "3";
BA_ "Confidence" SG_ 542 PARK_pscParkInstruction 0;
BA_ "GenSigSNA" SG_ 542 PARK_pscParkInstruction "7";
BA_ "Confidence" SG_ 542 PARK_pscManeuverDistance 0;
BA_ "GenSigSNA" SG_ 542 PARK_pscManeuverDistance "2047";
BA_ "Confidence" SG_ 542 PARK_pscAngleActive 0;
BA_ "Confidence" SG_ 542 PARK_pscAngleRequest 0;
BA_ "Confidence" SG_ 542 PARK_pscStatusCounter 0;
BA_ "Confidence" SG_ 542 PARK_pscStatusChecksum 0;
BA_ "Confidence" SG_ 590 PARK_pscVehSlotType 1;
BA_ "Confidence" SG_ 590 PARK_pscLeftParallelVehX 0;
BA_ "GenSigSNA" SG_ 590 PARK_pscLeftParallelVehX "2047";
BA_ "Confidence" SG_ 590 PARK_pscLeftParallelVehY 0;
BA_ "GenSigSNA" SG_ 590 PARK_pscLeftParallelVehY "2047";
BA_ "Confidence" SG_ 590 PARK_pscLeftParallelPsi 0;
BA_ "GenSigSNA" SG_ 590 PARK_pscLeftParallelPsi "8191";
BA_ "Confidence" SG_ 590 PARK_pscLeftParallelSizeX 0;
BA_ "GenSigSNA" SG_ 590 PARK_pscLeftParallelSizeX "255";
BA_ "Confidence" SG_ 590 PARK_pscLeftParallelSizeY 0;
BA_ "GenSigSNA" SG_ 590 PARK_pscLeftParallelSizeY "255";
BA_ "Confidence" SG_ 590 PARK_pscLeftCrossVehX 0;
BA_ "GenSigSNA" SG_ 590 PARK_pscLeftCrossVehX "2047";
BA_ "Confidence" SG_ 590 PARK_pscLeftCrossVehY 0;
BA_ "GenSigSNA" SG_ 590 PARK_pscLeftCrossVehY "2047";
BA_ "Confidence" SG_ 590 PARK_pscLeftCrossPsi 0;
BA_ "GenSigSNA" SG_ 590 PARK_pscLeftCrossPsi "8191";
BA_ "Confidence" SG_ 590 PARK_pscLeftCrossSizeX 0;
BA_ "GenSigSNA" SG_ 590 PARK_pscLeftCrossSizeX "255";
BA_ "Confidence" SG_ 590 PARK_pscLeftCrossSizeY 0;
BA_ "GenSigSNA" SG_ 590 PARK_pscLeftCrossSizeY "255";
BA_ "Confidence" SG_ 590 PARK_pscRightParallelVehX 0;
BA_ "GenSigSNA" SG_ 590 PARK_pscRightParallelVehX "2047";
BA_ "Confidence" SG_ 590 PARK_pscRightParallelVehY 0;
BA_ "GenSigSNA" SG_ 590 PARK_pscRightParallelVehY "2047";
BA_ "Confidence" SG_ 590 PARK_pscRightParallelPsi 0;
BA_ "GenSigSNA" SG_ 590 PARK_pscRightParallelPsi "8191";
BA_ "Confidence" SG_ 590 PARK_pscRightParallelSizeX 0;
BA_ "GenSigSNA" SG_ 590 PARK_pscRightParallelSizeX "255";
BA_ "Confidence" SG_ 590 PARK_pscRightParallelSizeY 0;
BA_ "GenSigSNA" SG_ 590 PARK_pscRightParallelSizeY "255";
BA_ "Confidence" SG_ 590 PARK_pscRightCrossVehX 0;
BA_ "GenSigSNA" SG_ 590 PARK_pscRightCrossVehX "2047";
BA_ "Confidence" SG_ 590 PARK_pscRightCrossVehY 0;
BA_ "GenSigSNA" SG_ 590 PARK_pscRightCrossVehY "2047";
BA_ "Confidence" SG_ 590 PARK_pscRightCrossPsi 0;
BA_ "GenSigSNA" SG_ 590 PARK_pscRightCrossPsi "8191";
BA_ "Confidence" SG_ 590 PARK_pscRightCrossSizeX 0;
BA_ "GenSigSNA" SG_ 590 PARK_pscRightCrossSizeX "255";
BA_ "Confidence" SG_ 590 PARK_pscRightCrossSizeY 0;
BA_ "GenSigSNA" SG_ 590 PARK_pscRightCrossSizeY "255";
BA_ "Confidence" SG_ 526 PARK_sdiSensor1RawDistData 0;
BA_ "GenSigSNA" SG_ 526 PARK_sdiSensor1RawDistData "511";
BA_ "Confidence" SG_ 526 PARK_sdiSensor2RawDistData 0;
BA_ "GenSigSNA" SG_ 526 PARK_sdiSensor2RawDistData "511";
BA_ "Confidence" SG_ 526 PARK_sdiSensor3RawDistData 0;
BA_ "GenSigSNA" SG_ 526 PARK_sdiSensor3RawDistData "511";
BA_ "Confidence" SG_ 526 PARK_sdiSensor4RawDistData 0;
BA_ "GenSigSNA" SG_ 526 PARK_sdiSensor4RawDistData "511";
BA_ "Confidence" SG_ 526 PARK_sdiSensor5RawDistData 0;
BA_ "GenSigSNA" SG_ 526 PARK_sdiSensor5RawDistData "511";
BA_ "Confidence" SG_ 526 PARK_sdiSensor6RawDistData 0;
BA_ "GenSigSNA" SG_ 526 PARK_sdiSensor6RawDistData "511";
BA_ "Confidence" SG_ 526 PARK_sdiFrontCounter 0;
BA_ "Confidence" SG_ 526 PARK_sdiFrontChecksum 0;
BA_ "Confidence" SG_ 558 PARK_sdiSensor7RawDistData 0;
BA_ "GenSigSNA" SG_ 558 PARK_sdiSensor7RawDistData "511";
BA_ "Confidence" SG_ 558 PARK_sdiSensor8RawDistData 0;
BA_ "GenSigSNA" SG_ 558 PARK_sdiSensor8RawDistData "511";
BA_ "Confidence" SG_ 558 PARK_sdiSensor9RawDistData 0;
BA_ "GenSigSNA" SG_ 558 PARK_sdiSensor9RawDistData "511";
BA_ "Confidence" SG_ 558 PARK_sdiSensor10RawDistData 0;
BA_ "GenSigSNA" SG_ 558 PARK_sdiSensor10RawDistData "511";
BA_ "Confidence" SG_ 558 PARK_sdiSensor11RawDistData 0;
BA_ "GenSigSNA" SG_ 558 PARK_sdiSensor11RawDistData "511";
BA_ "Confidence" SG_ 558 PARK_sdiSensor12RawDistData 0;
BA_ "GenSigSNA" SG_ 558 PARK_sdiSensor12RawDistData "511";
BA_ "Confidence" SG_ 558 PARK_sdiRearCounter 0;
BA_ "Confidence" SG_ 558 PARK_sdiRearChecksum 0;
BA_ "Confidence" SG_ 814 PARK_frontRightSensorState 0;
BA_ "GenSigSNA" SG_ 814 PARK_frontRightSensorState "3";
BA_ "Confidence" SG_ 814 PARK_frontRightMiddleSensorState 0;
BA_ "GenSigSNA" SG_ 814 PARK_frontRightMiddleSensorState "3";
BA_ "Confidence" SG_ 814 PARK_frontLeftMiddleSensorState 0;
BA_ "GenSigSNA" SG_ 814 PARK_frontLeftMiddleSensorState "3";
BA_ "Confidence" SG_ 814 PARK_frontLeftSensorState 0;
BA_ "GenSigSNA" SG_ 814 PARK_frontLeftSensorState "3";
BA_ "Confidence" SG_ 814 PARK_frontLeftRawDistData 0;
BA_ "GenSigSNA" SG_ 814 PARK_frontLeftRawDistData "255";
BA_ "Confidence" SG_ 814 PARK_frontRightRawDistData 0;
BA_ "GenSigSNA" SG_ 814 PARK_frontRightRawDistData "255";
BA_ "Confidence" SG_ 814 PARK_systemStatusFront 0;
BA_ "GenSigSNA" SG_ 814 PARK_systemStatusFront "3";
BA_ "Confidence" SG_ 814 PARK_frontDtcPresent 0;
BA_ "GenSigSNA" SG_ 814 PARK_frontDtcPresent "3";
BA_ "Confidence" SG_ 814 PARK_sensorStatusFrontCounter 0;
BA_ "Confidence" SG_ 814 PARK_sensorStatusFrontChecksum 0;
BA_ "Confidence" SG_ 830 PARK_rearRightSensorState 0;
BA_ "GenSigSNA" SG_ 830 PARK_rearRightSensorState "3";
BA_ "Confidence" SG_ 830 PARK_rearRightMiddleSensorState 0;
BA_ "GenSigSNA" SG_ 830 PARK_rearRightMiddleSensorState "3";
BA_ "Confidence" SG_ 830 PARK_rearLeftMiddleSensorState 0;
BA_ "GenSigSNA" SG_ 830 PARK_rearLeftMiddleSensorState "3";
BA_ "Confidence" SG_ 830 PARK_rearLeftSensorState 0;
BA_ "GenSigSNA" SG_ 830 PARK_rearLeftSensorState "3";
BA_ "Confidence" SG_ 830 PARK_rearLeftRawDistData 0;
BA_ "GenSigSNA" SG_ 830 PARK_rearLeftRawDistData "255";
BA_ "Confidence" SG_ 830 PARK_rearRightRawDistData 0;
BA_ "GenSigSNA" SG_ 830 PARK_rearRightRawDistData "255";
BA_ "Confidence" SG_ 830 PARK_systemStatusRear 0;
BA_ "GenSigSNA" SG_ 830 PARK_systemStatusRear "3";
BA_ "Confidence" SG_ 830 PARK_rearDtcPresent 0;
BA_ "GenSigSNA" SG_ 830 PARK_rearDtcPresent "3";
BA_ "Confidence" SG_ 830 PARK_sensorStatusRearCounter 0;
BA_ "Confidence" SG_ 830 PARK_sensorStatusRearChecksum 0;
BA_ "Confidence" SG_ 798 PARK_status 0;
BA_ "GenSigSNA" SG_ 798 PARK_status "3";
BA_ "Confidence" SG_ 798 PARK_serviceRequest 0;
BA_ "GenSigSNA" SG_ 798 PARK_serviceRequest "3";
BA_ "Confidence" SG_ 798 PARK_systemDtcPresent 0;
BA_ "GenSigSNA" SG_ 798 PARK_systemDtcPresent "3";
BA_ "Confidence" SG_ 798 PARK_statusCounter 0;
BA_ "Confidence" SG_ 798 PARK_statusChecksum 0;
BA_ "Confidence" SG_ 798 PARK_majorVersion 0;
BA_ "GenSigSNA" SG_ 798 PARK_majorVersion "255";
BA_ "Confidence" SG_ 798 PARK_minorVersion 0;
BA_ "GenSigSNA" SG_ 798 PARK_minorVersion "255";
BA_ "Confidence" SG_ 798 PARK_subMinorVersion 0;
BA_ "GenSigSNA" SG_ 798 PARK_subMinorVersion "255";
BA_ "Confidence" SG_ 782 PARK_frontSVACharID 0;
BA_ "Confidence" SG_ 782 PARK_pscRightCurbType 0;
BA_ "Confidence" SG_ 782 PARK_rearSVACharID 0;
BA_ "Confidence" SG_ 782 PARK_pscLeftCurbType 0;
BA_ "Confidence" SG_ 782 PARK_autoCalComplete 0;
BA_ "Confidence" SG_ 782 PARK_geometryType 0;
BA_ "Confidence" SG_ 782 PARK_tireFitment 0;
BA_ "GenSigSNA" SG_ 782 PARK_tireFitment "3";
BA_ "Confidence" SG_ 782 PARK_rackDetected 0;
BA_ "GenSigSNA" SG_ 782 PARK_rackDetected "3";
BA_ "Confidence" SG_ 782 PARK_sdiActive 0;
BA_ "Confidence" SG_ 782 PARK_sdiNoise 0;
BA_ "GenSigSNA" SG_ 782 PARK_sdiNoise "3";
BA_ "Confidence" SG_ 782 PARK_sdiBlindSpotRight 0;
BA_ "GenSigSNA" SG_ 782 PARK_sdiBlindSpotRight "3";
BA_ "Confidence" SG_ 782 PARK_sdiBlindSpotLeft 0;
BA_ "GenSigSNA" SG_ 782 PARK_sdiBlindSpotLeft "3";
BA_ "Confidence" SG_ 782 PARK_sensorType 0;
BA_ "GenSigSNA" SG_ 782 PARK_sensorType "3";
BA_ "Confidence" SG_ 782 PARK_status2Counter 0;
BA_ "Confidence" SG_ 782 PARK_status2Checksum 0;
BA_ "Confidence" SG_ 1329 RADC_infoIndex 1;
BA_ "Confidence" SG_ 1329 RADC_infoBuildType 0;
BA_ "Confidence" SG_ 1329 RADC_infoBuildConfigID 0;
BA_ "Confidence" SG_ 1329 RADC_infoHardwareID 0;
BA_ "Confidence" SG_ 1329 RADC_infoComponentID 0;
BA_ "Confidence" SG_ 1329 RADC_infoPcbaID 0;
BA_ "Confidence" SG_ 1329 RADC_infoAssemblyID 0;
BA_ "Confidence" SG_ 1329 RADC_infoUsageID 0;
BA_ "Confidence" SG_ 1329 RADC_infoSubUsageID 0;
BA_ "Confidence" SG_ 1329 RADC_infoApplicationCRC 0;
BA_ "Confidence" SG_ 1329 RADC_infoPlatformType 0;
BA_ "Confidence" SG_ 1329 RADC_infoMajorVersion 0;
BA_ "Confidence" SG_ 1329 RADC_infoBranchOrigin 0;
BA_ "Confidence" SG_ 1329 RADC_infoMaturity 0;
BA_ "Confidence" SG_ 1329 RADC_infoHardwareRevision 0;
BA_ "Confidence" SG_ 1329 RADC_infoBootUdsProtoVersion 0;
BA_ "Confidence" SG_ 1329 RADC_infoBootloaderCRC 0;
BA_ "Confidence" SG_ 257 RCM_yawRate 0;
BA_ "GenSigSNA" SG_ 257 RCM_yawRate "32768";
BA_ "Confidence" SG_ 257 RCM_pitchRate 0;
BA_ "GenSigSNA" SG_ 257 RCM_pitchRate "16384";
BA_ "Confidence" SG_ 257 RCM_rollRate 0;
BA_ "GenSigSNA" SG_ 257 RCM_rollRate "16384";
BA_ "Confidence" SG_ 257 RCM_rollRateQF 0;
BA_ "Confidence" SG_ 257 RCM_yawRateQF 0;
BA_ "Confidence" SG_ 257 RCM_pitchRateQF 0;
BA_ "Confidence" SG_ 257 RCM_inertial1Counter 0;
BA_ "Confidence" SG_ 257 RCM_inertial1Checksum 0;
BA_ "Confidence" SG_ 273 RCM_longitudinalAccel 0;
BA_ "GenSigSNA" SG_ 273 RCM_longitudinalAccel "32768";
BA_ "Confidence" SG_ 273 RCM_lateralAccel 0;
BA_ "GenSigSNA" SG_ 273 RCM_lateralAccel "32768";
BA_ "Confidence" SG_ 273 RCM_verticalAccel 0;
BA_ "GenSigSNA" SG_ 273 RCM_verticalAccel "32768";
BA_ "Confidence" SG_ 273 RCM_longitudinalAccelQF 0;
BA_ "Confidence" SG_ 273 RCM_lateralAccelQF 0;
BA_ "Confidence" SG_ 273 RCM_verticalAccelQF 0;
BA_ "Confidence" SG_ 273 RCM_CGTranslationFault 0;
BA_ "Confidence" SG_ 273 RCM_inertial2Counter 0;
BA_ "Confidence" SG_ 273 RCM_inertial2Checksum 0;
BA_ "Confidence" SG_ 849 RCM_infoIndex 1;
BA_ "Confidence" SG_ 849 RCM_infoBuildType 0;
BA_ "Confidence" SG_ 849 RCM_infoComponentID 0;
BA_ "Confidence" SG_ 849 RCM_infoPcbaID 0;
BA_ "Confidence" SG_ 849 RCM_infoAssemblyID 0;
BA_ "Confidence" SG_ 849 RCM_infoUsageID 0;
BA_ "Confidence" SG_ 849 RCM_infoApplicationCRC 0;
BA_ "Confidence" SG_ 849 RCM_infoBootUdsProtoVersion 0;
BA_ "Confidence" SG_ 849 RCM_infoBootloaderCRC 0;
BA_ "Confidence" SG_ 849 RCM_infoAlgoCalID 0;
BA_ "Confidence" SG_ 849 RCM_infoVariantCRC 0;
BA_ "Confidence" SG_ 529 RCM_statusChecksum 0;
BA_ "Confidence" SG_ 529 RCM_statusCounter 0;
BA_ "Confidence" SG_ 529 RCM_armStatus 0;
BA_ "GenSigSNA" SG_ 529 RCM_armStatus "3";
BA_ "Confidence" SG_ 529 RCM_warningIndicatorState 0;
BA_ "GenSigSNA" SG_ 529 RCM_warningIndicatorState "3";
BA_ "Confidence" SG_ 529 RCM_passAirbagIndicatorRequest 0;
BA_ "GenSigSNA" SG_ 529 RCM_passAirbagIndicatorRequest "3";
BA_ "Confidence" SG_ 529 RCM_airbagCutoffStatus 0;
BA_ "GenSigSNA" SG_ 529 RCM_airbagCutoffStatus "3";
BA_ "Confidence" SG_ 529 RCM_alrSwitchStatus 0;
BA_ "GenSigSNA" SG_ 529 RCM_alrSwitchStatus "3";
BA_ "Confidence" SG_ 529 RCM_vinLearnFlag 0;
BA_ "GenSigSNA" SG_ 529 RCM_vinLearnFlag "3";
BA_ "Confidence" SG_ 529 RCM_seatTrackPositionDrvr 0;
BA_ "GenSigSNA" SG_ 529 RCM_seatTrackPositionDrvr "3";
BA_ "Confidence" SG_ 529 RCM_seatTrackPositionPass 0;
BA_ "GenSigSNA" SG_ 529 RCM_seatTrackPositionPass "3";
BA_ "Confidence" SG_ 529 RCM_edr1State 0;
BA_ "Confidence" SG_ 529 RCM_edr2State 0;
BA_ "Confidence" SG_ 529 RCM_keepPowerReason 0;
BA_ "GenSigSNA" SG_ 529 RCM_keepPowerReason "8";
BA_ "Confidence" SG_ 529 RCM_imuOffsetLearnState 0;
BA_ "Confidence" SG_ 529 RCM_edr3State 0;
BA_ "Confidence" SG_ 529 RCM_driverOrientationInitStatus 0;
BA_ "GenSigSNA" SG_ 529 RCM_driverOrientationInitStatus "7";
BA_ "Confidence" SG_ 529 RCM_occupantClassificationSource 0;
BA_ "Confidence" SG_ 529 RCM_pedProEDR1State 0;
BA_ "Confidence" SG_ 529 RCM_pedProEDR2State 0;
BA_ "Confidence" SG_ 879 TPMS_c_globalHardWarning 0;
BA_ "Confidence" SG_ 879 TPMS_c_globalSoftWarning 0;
BA_ "Confidence" SG_ 879 TPMS_systemMalfunction 0;
BA_ "Confidence" SG_ 879 TPMS_WA_version 0;
BA_ "Confidence" SG_ 879 TPMS_globalDeltaPressure 0;
BA_ "Confidence" SG_ 879 TPMS_newSensorLearnt 0;
BA_ "Confidence" SG_ 879 TPMS_softWarningRR 0;
BA_ "Confidence" SG_ 879 TPMS_hardWarningRR 0;
BA_ "Confidence" SG_ 879 TPMS_softWarningRL 0;
BA_ "Confidence" SG_ 879 TPMS_hardWarningRL 0;
BA_ "Confidence" SG_ 879 TPMS_softWarningFR 0;
BA_ "Confidence" SG_ 879 TPMS_hardWarningFR 0;
BA_ "Confidence" SG_ 879 TPMS_softWarningFL 0;
BA_ "Confidence" SG_ 879 TPMS_hardWarningFL 0;
BA_ "Confidence" SG_ 879 TPMS_learningStatus 0;
BA_ "Confidence" SG_ 879 TPMS_localisationStatus 0;
BA_ "Confidence" SG_ 879 TPMS_deltaPressWarningFL 0;
BA_ "Confidence" SG_ 879 TPMS_deltaPressWarningFR 0;
BA_ "Confidence" SG_ 879 TPMS_deltaPressWarningRL 0;
BA_ "Confidence" SG_ 879 TPMS_deltaPressWarningRR 0;
BA_ "Confidence" SG_ 879 TPMS_sensorNoResponseFL 0;
BA_ "Confidence" SG_ 879 TPMS_sensorNoResponseFR 0;
BA_ "Confidence" SG_ 879 TPMS_sensorNoResponseRL 0;
BA_ "Confidence" SG_ 879 TPMS_sensorNoResponseRR 0;
BA_ "Confidence" SG_ 879 TPMS_sensorThermShutdownFL 0;
BA_ "Confidence" SG_ 879 TPMS_sensorThermShutdownFR 0;
BA_ "Confidence" SG_ 879 TPMS_sensorThermShutdownRL 0;
BA_ "Confidence" SG_ 879 TPMS_sensorThermShutdownRR 0;
BA_ "Confidence" SG_ 879 TPMS_sensorBatteryLowFL 0;
BA_ "Confidence" SG_ 879 TPMS_sensorBatteryLowFR 0;
BA_ "Confidence" SG_ 879 TPMS_sensorBatteryLowRL 0;
BA_ "Confidence" SG_ 879 TPMS_sensorBatteryLowRR 0;
BA_ "Confidence" SG_ 879 TPMS_sensorDefectiveFL 0;
BA_ "Confidence" SG_ 879 TPMS_sensorDefectiveFR 0;
BA_ "Confidence" SG_ 879 TPMS_sensorDefectiveRL 0;
BA_ "Confidence" SG_ 879 TPMS_sensorDefectiveRR 0;
BA_ "Confidence" SG_ 879 TPMS_ecuUnderVoltage 0;
BA_ "Confidence" SG_ 879 TPMS_ecuOverVoltage 0;
BA_ "Confidence" SG_ 879 TPMS_ecuRamRomNvMFail 0;
BA_ "Confidence" SG_ 879 TPMS_rfReceiverFail 0;
BA_ "Confidence" SG_ 879 TPMS_wheelPulseMissing 0;
BA_ "Confidence" SG_ 879 TPMS_vehicleSpeedFail 0;
BA_ "Confidence" SG_ 879 TPMS_externalTemperatureFail 0;
BA_ "Confidence" SG_ 879 TPMS_eolNotCompleted 0;
BA_ "Confidence" SG_ 879 TPMS_rcpFront 0;
BA_ "Confidence" SG_ 879 TPMS_rcpRear 0;
BA_ "Confidence" SG_ 799 TPMS_pressureFL 0;
BA_ "GenSigSNA" SG_ 799 TPMS_pressureFL "255";
BA_ "Confidence" SG_ 799 TPMS_temperatureFL 0;
BA_ "GenSigSNA" SG_ 799 TPMS_temperatureFL "255";
BA_ "Confidence" SG_ 799 TPMS_pressureFR 0;
BA_ "GenSigSNA" SG_ 799 TPMS_pressureFR "255";
BA_ "Confidence" SG_ 799 TPMS_temperatureFR 0;
BA_ "GenSigSNA" SG_ 799 TPMS_temperatureFR "255";
BA_ "Confidence" SG_ 799 TPMS_pressureRL 0;
BA_ "GenSigSNA" SG_ 799 TPMS_pressureRL "255";
BA_ "Confidence" SG_ 799 TPMS_temperatureRL 0;
BA_ "GenSigSNA" SG_ 799 TPMS_temperatureRL "255";
BA_ "Confidence" SG_ 799 TPMS_pressureRR 0;
BA_ "GenSigSNA" SG_ 799 TPMS_pressureRR "255";
BA_ "Confidence" SG_ 799 TPMS_temperatureRR 0;
BA_ "GenSigSNA" SG_ 799 TPMS_temperatureRR "255";
BA_ "Confidence" SG_ 1519 TPMS_infoIndex 1;
BA_ "Confidence" SG_ 1519 TPMS_infoComponentID 0;
BA_ "Confidence" SG_ 1519 TPMS_infoPcbaID 0;
BA_ "Confidence" SG_ 1519 TPMS_infoAssemblyID 0;
BA_ "Confidence" SG_ 1519 TPMS_infoUsageID 0;
BA_ "Confidence" SG_ 1519 TPMS_infoApplicationCRC 0;
BA_ "Confidence" SG_ 1519 TPMS_infoBootUdsProtoVersion 0;
BA_ "Confidence" SG_ 1519 TPMS_infoBootloaderCRC 0;
BA_ "Confidence" SG_ 659 UI_steeringTuneRequest 0;
BA_ "Confidence" SG_ 659 UI_tractionControlMode 0;
BA_ "Confidence" SG_ 659 UI_parkBrakeRequest 0;
BA_ "GenSigSNA" SG_ 659 UI_parkBrakeRequest "3";
BA_ "Confidence" SG_ 659 UI_winchModeRequest 0;
BA_ "Confidence" SG_ 659 UI_trailerMode 0;
BA_ "Confidence" SG_ 659 UI_accOvertakeEnable 0;
BA_ "GenSigSNA" SG_ 659 UI_accOvertakeEnable "3";
BA_ "Confidence" SG_ 659 UI_aebEnable 0;
BA_ "GenSigSNA" SG_ 659 UI_aebEnable "3";
BA_ "Confidence" SG_ 659 UI_aesEnable 0;
BA_ "GenSigSNA" SG_ 659 UI_aesEnable "3";
BA_ "Confidence" SG_ 659 UI_ahlbEnable 0;
BA_ "GenSigSNA" SG_ 659 UI_ahlbEnable "3";
BA_ "Confidence" SG_ 659 UI_autoLaneChangeEnable 0;
BA_ "GenSigSNA" SG_ 659 UI_autoLaneChangeEnable "3";
BA_ "Confidence" SG_ 659 UI_winchProxUserOverride 0;
BA_ "Confidence" SG_ 659 UI_autoParkRequest 0;
BA_ "GenSigSNA" SG_ 659 UI_autoParkRequest "15";
BA_ "Confidence" SG_ 659 UI_bsdEnable 0;
BA_ "GenSigSNA" SG_ 659 UI_bsdEnable "3";
BA_ "Confidence" SG_ 659 UI_fcwEnable 0;
BA_ "GenSigSNA" SG_ 659 UI_fcwEnable "3";
BA_ "Confidence" SG_ 659 UI_fcwSensitivity 0;
BA_ "GenSigSNA" SG_ 659 UI_fcwSensitivity "3";
BA_ "Confidence" SG_ 659 UI_latControlEnable 0;
BA_ "GenSigSNA" SG_ 659 UI_latControlEnable "3";
BA_ "Confidence" SG_ 659 UI_ldwEnable 0;
BA_ "GenSigSNA" SG_ 659 UI_ldwEnable "3";
BA_ "Confidence" SG_ 1016 UI_ulcStalkConfirm 0;
BA_ "Confidence" SG_ 1016 UI_lssLkaEnabled 0;
BA_ "Confidence" SG_ 1016 UI_lssLdwEnabled 0;
BA_ "Confidence" SG_ 1016 UI_driveOnMapsEnable 0;
BA_ "Confidence" SG_ 1016 UI_lssElkEnabled 0;
BA_ "Confidence" SG_ 1016 UI_selfParkRequest 0;
BA_ "GenSigSNA" SG_ 1016 UI_selfParkRequest "15";
BA_ "Confidence" SG_ 1016 UI_followNavRouteEnable 0;
BA_ "Confidence" SG_ 1016 UI_ulcSpeedConfig 0;
BA_ "Confidence" SG_ 1016 UI_suppressExitPassingLane 0;
BA_ "Confidence" SG_ 1016 UI_smartSummonType 0;
BA_ "Confidence" SG_ 1016 UI_isaSpeedingChimeMuted 0;
BA_ "Confidence" SG_ 568 UI_roadClass 0;
BA_ "GenSigSNA" SG_ 568 UI_roadClass "0";
BA_ "Confidence" SG_ 568 UI_navRouteActive 0;
BA_ "Confidence" SG_ 568 UI_parallelAutoparkEnabled 0;
BA_ "Confidence" SG_ 568 UI_perpendicularAutoparkEnabled 0;
BA_ "Confidence" SG_ 568 UI_controlledAccess 0;
BA_ "Confidence" SG_ 568 UI_autosteerRestricted 0;
BA_ "Confidence" SG_ 760 UI_mapSpeedLimitUnits 0;
BA_ "Confidence" SG_ 760 UI_mppSpeedLimit 0;
BA_ "Confidence" SG_ 760 UI_gpsNmeaMIA 0;
BA_ "Confidence" SG_ 760 UI_gpsAntennaDisconnected 0;
BA_ "Confidence" SG_ 760 UI_conditionalLimitActive 0;
BA_ "Confidence" SG_ 760 UI_conditionalSpeedLimit 0;
BA_ "GenSigSNA" SG_ 760 UI_conditionalSpeedLimit "31";
BA_ "Confidence" SG_ 1011 UI_odometer 0;
BA_ "GenSigSNA" SG_ 1011 UI_odometer "16777215";
BA_ "Confidence" SG_ 723 UI_isSunUp 0;
BA_ "GenSigSNA" SG_ 723 UI_isSunUp "3";
BA_ "Confidence" SG_ 723 UI_solarElevationAngle 0;
BA_ "GenSigSNA" SG_ 723 UI_solarElevationAngle "127";
BA_ "Confidence" SG_ 723 UI_screenPCBTemperature 0;
BA_ "Confidence" SG_ 723 UI_minsToSunset 0;
BA_ "Confidence" SG_ 723 UI_minsToSunrise 0;
BA_ "Confidence" SG_ 851 UI_touchActive 0;
BA_ "Confidence" SG_ 851 UI_audioActive 0;
BA_ "Confidence" SG_ 851 UI_cellActive 0;
BA_ "Confidence" SG_ 851 UI_displayReady 0;
BA_ "Confidence" SG_ 851 UI_displayOn 0;
BA_ "Confidence" SG_ 851 UI_wifiActive 0;
BA_ "Confidence" SG_ 851 UI_wifiConnected 0;
BA_ "Confidence" SG_ 851 UI_readyForDrive 0;
BA_ "Confidence" SG_ 851 UI_cellConnected 0;
BA_ "Confidence" SG_ 851 UI_vpnActive 0;
BA_ "Confidence" SG_ 851 UI_factoryReset 0;
BA_ "GenSigSNA" SG_ 851 UI_factoryReset "0";
BA_ "Confidence" SG_ 851 UI_gpsActive 0;
BA_ "Confidence" SG_ 851 UI_cellNetworkTechnology 0;
BA_ "GenSigSNA" SG_ 851 UI_cellNetworkTechnology "15";
BA_ "Confidence" SG_ 851 UI_falseTouchCounter 0;
BA_ "Confidence" SG_ 851 UI_cellSignalBars 0;
BA_ "GenSigSNA" SG_ 851 UI_cellSignalBars "7";
BA_ "Confidence" SG_ 851 UI_trailerModeTelltale 0;
BA_ "Confidence" SG_ 851 UI_pcbTemperature 0;
BA_ "Confidence" SG_ 851 UI_cpuTemperature 0;
BA_ "Confidence" SG_ 807 USM_infoIndex 1;
BA_ "Confidence" SG_ 807 USM_infoBuildType 0;
BA_ "Confidence" SG_ 807 USM_infoBuildConfigId 0;
BA_ "Confidence" SG_ 807 USM_infoHardwareId 0;
BA_ "Confidence" SG_ 807 USM_infoComponentId 0;
BA_ "Confidence" SG_ 807 USM_infoPcbaId 0;
BA_ "Confidence" SG_ 807 USM_infoAssemblyId 0;
BA_ "GenSigSNA" SG_ 807 USM_infoAssemblyId "255";
BA_ "Confidence" SG_ 807 USM_infoUsageId 0;
BA_ "Confidence" SG_ 807 USM_infoSubUsageId 0;
BA_ "Confidence" SG_ 807 USM_infoAppCrc 0;
VAL_ 606 PARK_pscEnvSlotType 3 "RIGHT_CROSS" 2 "RIGHT_PARALLEL" 1 "LEFT_CROSS" 0 "LEFT_PARALLEL" ;
VAL_ 606 PARK_pscLeftParallelObj1X 2047 "SNA" 2046 "NO_SPACE" ;
VAL_ 606 PARK_pscLeftParallelObj1Y 2047 "SNA" 2046 "NO_SPACE" ;
VAL_ 606 PARK_pscLeftParallelObj1Alpha 127 "SNA" 126 "NO_SPACE" ;
VAL_ 606 PARK_pscLeftParallelObj2Y 2047 "SNA" 2046 "NO_SPACE" ;
VAL_ 606 PARK_pscLeftParallelObj2X 2047 "SNA" 2046 "NO_SPACE" ;
VAL_ 606 PARK_pscLeftParallelObj2Alpha 127 "SNA" 126 "NO_SPACE" ;
VAL_ 606 PARK_pscLeftCrossObj1X 2047 "SNA" 2046 "NO_SPACE" ;
VAL_ 606 PARK_pscLeftCrossObj1Y 2047 "SNA" 2046 "NO_SPACE" ;
VAL_ 606 PARK_pscLeftCrossObj1Alpha 127 "SNA" 126 "NO_SPACE" ;
VAL_ 606 PARK_pscLeftCrossObj2Y 2047 "SNA" 2046 "NO_SPACE" ;
VAL_ 606 PARK_pscLeftCrossObj2X 2047 "SNA" 2046 "NO_SPACE" ;
VAL_ 606 PARK_pscLeftCrossObj2Alpha 127 "SNA" 126 "NO_SPACE" ;
VAL_ 606 PARK_pscRightParallelObj1X 2047 "SNA" 2046 "NO_SPACE" ;
VAL_ 606 PARK_pscRightParallelObj1Y 2047 "SNA" 2046 "NO_SPACE" ;
VAL_ 606 PARK_pscRightParallelObj1Alpha 127 "SNA" 126 "NO_SPACE" ;
VAL_ 606 PARK_pscRightParallelObj2Y 2047 "SNA" 2046 "NO_SPACE" ;
VAL_ 606 PARK_pscRightParallelObj2X 2047 "SNA" 2046 "NO_SPACE" ;
VAL_ 606 PARK_pscRightParallelObj2Alpha 127 "SNA" 126 "NO_SPACE" ;
VAL_ 606 PARK_pscRightCrossObj1X 2047 "SNA" 2046 "NO_SPACE" ;
VAL_ 606 PARK_pscRightCrossObj1Y 2047 "SNA" 2046 "NO_SPACE" ;
VAL_ 606 PARK_pscRightCrossObj1Alpha 127 "SNA" 126 "NO_SPACE" ;
VAL_ 606 PARK_pscRightCrossObj2Y 2047 "SNA" 2046 "NO_SPACE" ;
VAL_ 606 PARK_pscRightCrossObj2X 2047 "SNA" 2046 "NO_SPACE" ;
VAL_ 606 PARK_pscRightCrossObj2Alpha 127 "SNA" 126 "NO_SPACE" ;
VAL_ 542 PARK_pscParkStatus 7 "SNA" 6 "FAULT" 5 "GUIDANCE_FINISHED" 4 "PRE_GUIDANCE" 3 "GUIDANCE_RIGHT" 2 "GUIDANCE_LEFT" 1 "SEARCHING" 0 "NOT_AVAILABLE" ;
VAL_ 542 PARK_pscParkAbortReason 31 "SNA" 25 "PSC_MOVEMENT_AT_ACTIVATION" 24 "PSC_MAX_WAY_BEHIND_HINT" 23 "PSC_PARK_STC_FAILED" 22 "PSC_PARK_PONR_NOT_REACHED" 21 "PSC_VCTL_GENERAL_ABORT" 20 "PSC_HIGH_TORQUE" 19 "PSC_ASYNC_CTRL_SYSTEM" 18 "ERROR" 17 "SYSTEM_SERVICE" 16 "SYSTEM_FAULT" 15 "ECU_INTERNAL_FAULT" 14 "DAS_ABORT" 13 "EPAS_FAULT" 12 "VEHICLE_DYNAMICS_INTERVENTION" 11 "HANDS_ON_DETECTED" 10 "FULL_WARNING_ON_BOTH_SIDES" 9 "PARK_SPACE_TOO_SMALL" 8 "OBSTACLE_ON_PATH" 7 "MAX_YAW_ANGLE_REACHED" 6 "MAX_SWA_DEV_EXCEEDED" 5 "OFF_TRACK" 4 "UNCONTROLLED_TRAVEL_DIST_REACHED" 3 "NO_VALID_PATH" 2 "MAX_NUM_OF_MOVES" 1 "VELOCITY_TOO_HIGH" 0 "NONE" ;
VAL_ 542 PARK_pscParallelSpace 3 "BOTH_AVAILABLE" 2 "LEFT_AVAILABLE" 1 "RIGHT_AVAILABLE" 0 "NONE_AVAILABLE" ;
VAL_ 542 PARK_pscCrossSpace 3 "BOTH_AVAILABLE" 2 "LEFT_AVAILABLE" 1 "RIGHT_AVAILABLE" 0 "NONE_AVAILABLE" ;
VAL_ 542 PARK_pscParallelRightParkable 3 "SNA" 2 "PARKING_SLOT_OK_POSITION_OK" 1 "PARKING_SLOT_OK" 0 "NONE" ;
VAL_ 542 PARK_pscParallelLeftParkable 3 "SNA" 2 "PARKING_SLOT_OK_POSITION_OK" 1 "PARKING_SLOT_OK" 0 "NONE" ;
VAL_ 542 PARK_pscCrossRightParkable 3 "SNA" 2 "PARKING_SLOT_OK_POSITION_OK" 1 "PARKING_SLOT_OK" 0 "NONE" ;
VAL_ 542 PARK_pscMaxVelocity 63 "SNA" ;
VAL_ 542 PARK_pscCrossLeftParkable 3 "SNA" 2 "PARKING_SLOT_OK_POSITION_OK" 1 "PARKING_SLOT_OK" 0 "NONE" ;
VAL_ 542 PARK_pscParkInstruction 7 "SNA" 5 "EXPLORATION" 4 "ABORTED" 3 "DRIVE_BACKWARD" 2 "DRIVE_FORWARD" 1 "STOP" 0 "NO_MESSAGE" ;
VAL_ 542 PARK_pscManeuverDistance 2047 "SNA" ;
VAL_ 542 PARK_pscAngleActive 1 "REQUEST_CONTROL" 0 "INACTIVE" ;
VAL_ 590 PARK_pscVehSlotType 3 "RIGHT_CROSS" 2 "RIGHT_PARALLEL" 1 "LEFT_CROSS" 0 "LEFT_PARALLEL" ;
VAL_ 590 PARK_pscLeftParallelVehX 2047 "SNA" 2046 "NO_SPACE" ;
VAL_ 590 PARK_pscLeftParallelVehY 2047 "SNA" 2046 "NO_SPACE" ;
VAL_ 590 PARK_pscLeftParallelPsi 8191 "SNA" 8190 "NO_SPACE" ;
VAL_ 590 PARK_pscLeftParallelSizeX 255 "SNA" 254 "NO_SPACE" ;
VAL_ 590 PARK_pscLeftParallelSizeY 255 "SNA" 254 "NO_SPACE" ;
VAL_ 590 PARK_pscLeftCrossVehX 2047 "SNA" 2046 "NO_SPACE" ;
VAL_ 590 PARK_pscLeftCrossVehY 2047 "SNA" 2046 "NO_SPACE" ;
VAL_ 590 PARK_pscLeftCrossPsi 8191 "SNA" 8190 "NO_SPACE" ;
VAL_ 590 PARK_pscLeftCrossSizeX 255 "SNA" 254 "NO_SPACE" ;
VAL_ 590 PARK_pscLeftCrossSizeY 255 "SNA" 254 "NO_SPACE" ;
VAL_ 590 PARK_pscRightParallelVehX 2047 "SNA" 2046 "NO_SPACE" ;
VAL_ 590 PARK_pscRightParallelVehY 2047 "SNA" 2046 "NO_SPACE" ;
VAL_ 590 PARK_pscRightParallelPsi 8191 "SNA" 8190 "NO_SPACE" ;
VAL_ 590 PARK_pscRightParallelSizeX 255 "SNA" 254 "NO_SPACE" ;
VAL_ 590 PARK_pscRightParallelSizeY 255 "SNA" 254 "NO_SPACE" ;
VAL_ 590 PARK_pscRightCrossVehX 2047 "SNA" 2046 "NO_SPACE" ;
VAL_ 590 PARK_pscRightCrossVehY 2047 "SNA" 2046 "NO_SPACE" ;
VAL_ 590 PARK_pscRightCrossPsi 8191 "SNA" 8190 "NO_SPACE" ;
VAL_ 590 PARK_pscRightCrossSizeX 255 "SNA" 254 "NO_SPACE" ;
VAL_ 590 PARK_pscRightCrossSizeY 255 "SNA" 254 "NO_SPACE" ;
VAL_ 526 PARK_sdiSensor1RawDistData 511 "SNA" 500 "NO_OBJECT_DETECTED" 1 "NEAR_DETECTION" 0 "BLOCKED" ;
VAL_ 526 PARK_sdiSensor2RawDistData 511 "SNA" 500 "NO_OBJECT_DETECTED" 1 "NEAR_DETECTION" 0 "BLOCKED" ;
VAL_ 526 PARK_sdiSensor3RawDistData 511 "SNA" 500 "NO_OBJECT_DETECTED" 1 "NEAR_DETECTION" 0 "BLOCKED" ;
VAL_ 526 PARK_sdiSensor4RawDistData 511 "SNA" 500 "NO_OBJECT_DETECTED" 1 "NEAR_DETECTION" 0 "BLOCKED" ;
VAL_ 526 PARK_sdiSensor5RawDistData 511 "SNA" 500 "NO_OBJECT_DETECTED" 1 "NEAR_DETECTION" 0 "BLOCKED" ;
VAL_ 526 PARK_sdiSensor6RawDistData 511 "SNA" 500 "NO_OBJECT_DETECTED" 1 "NEAR_DETECTION" 0 "BLOCKED" ;
VAL_ 558 PARK_sdiSensor7RawDistData 511 "SNA" 500 "NO_OBJECT_DETECTED" 1 "NEAR_DETECTION" 0 "BLOCKED" ;
VAL_ 558 PARK_sdiSensor8RawDistData 511 "SNA" 500 "NO_OBJECT_DETECTED" 1 "NEAR_DETECTION" 0 "BLOCKED" ;
VAL_ 558 PARK_sdiSensor9RawDistData 511 "SNA" 500 "NO_OBJECT_DETECTED" 1 "NEAR_DETECTION" 0 "BLOCKED" ;
VAL_ 558 PARK_sdiSensor10RawDistData 511 "SNA" 500 "NO_OBJECT_DETECTED" 1 "NEAR_DETECTION" 0 "BLOCKED" ;
VAL_ 558 PARK_sdiSensor11RawDistData 511 "SNA" 500 "NO_OBJECT_DETECTED" 1 "NEAR_DETECTION" 0 "BLOCKED" ;
VAL_ 558 PARK_sdiSensor12RawDistData 511 "SNA" 500 "NO_OBJECT_DETECTED" 1 "NEAR_DETECTION" 0 "BLOCKED" ;
VAL_ 814 PARK_frontRightSensorState 3 "SNA" 2 "TEMPORARY_FAILURE" 1 "PERMANENT_FAILURE" 0 "NO_FAILURE" ;
VAL_ 814 PARK_frontRightMiddleSensorState 3 "SNA" 2 "TEMPORARY_FAILURE" 1 "PERMANENT_FAILURE" 0 "NO_FAILURE" ;
VAL_ 814 PARK_frontLeftMiddleSensorState 3 "SNA" 2 "TEMPORARY_FAILURE" 1 "PERMANENT_FAILURE" 0 "NO_FAILURE" ;
VAL_ 814 PARK_frontLeftSensorState 3 "SNA" 2 "TEMPORARY_FAILURE" 1 "PERMANENT_FAILURE" 0 "NO_FAILURE" ;
VAL_ 814 PARK_frontLeftRawDistData 255 "SNA" ;
VAL_ 814 PARK_frontRightRawDistData 255 "SNA" ;
VAL_ 814 PARK_systemStatusFront 3 "SNA" 2 "UNUSED" 1 "ENABLED" 0 "DISABLED" ;
VAL_ 814 PARK_frontDtcPresent 3 "SNA" 2 "UNUSED" 1 "TRUE" 0 "FALSE" ;
VAL_ 830 PARK_rearRightSensorState 3 "SNA" 2 "TEMPORARY_FAILURE" 1 "PERMANENT_FAILURE" 0 "NO_FAILURE" ;
VAL_ 830 PARK_rearRightMiddleSensorState 3 "SNA" 2 "TEMPORARY_FAILURE" 1 "PERMANENT_FAILURE" 0 "NO_FAILURE" ;
VAL_ 830 PARK_rearLeftMiddleSensorState 3 "SNA" 2 "TEMPORARY_FAILURE" 1 "PERMANENT_FAILURE" 0 "NO_FAILURE" ;
VAL_ 830 PARK_rearLeftSensorState 3 "SNA" 2 "TEMPORARY_FAILURE" 1 "PERMANENT_FAILURE" 0 "NO_FAILURE" ;
VAL_ 830 PARK_rearLeftRawDistData 255 "SNA" ;
VAL_ 830 PARK_rearRightRawDistData 255 "SNA" ;
VAL_ 830 PARK_systemStatusRear 3 "SNA" 2 "UNUSED" 1 "ENABLED" 0 "DISABLED" ;
VAL_ 830 PARK_rearDtcPresent 3 "SNA" 2 "UNUSED" 1 "TRUE" 0 "FALSE" ;
VAL_ 798 PARK_status 3 "SNA" 2 "TEMPORARY_FAILURE" 1 "ENABLED" 0 "DISABLED" ;
VAL_ 798 PARK_serviceRequest 3 "SNA" 2 "UNUSED" 1 "FAILURE" 0 "NO_FAILURE" ;
VAL_ 798 PARK_systemDtcPresent 3 "SNA" 2 "UNUSED" 1 "TRUE" 0 "FALSE" ;
VAL_ 798 PARK_majorVersion 255 "SNA" ;
VAL_ 798 PARK_minorVersion 255 "SNA" ;
VAL_ 798 PARK_subMinorVersion 255 "SNA" ;
VAL_ 782 PARK_pscRightCurbType 2 "HIGH_CURB" 1 "LOW_CURB" 0 "VIRTUAL_CURB" ;
VAL_ 782 PARK_pscLeftCurbType 2 "HIGH_CURB" 1 "LOW_CURB" 0 "VIRTUAL_CURB" ;
VAL_ 782 PARK_autoCalComplete 1 "COMPLETE" 0 "INCOMPLETE" ;
VAL_ 782 PARK_geometryType 3 "MODELY" 2 "MODEL3" 1 "MODELX" 0 "MODELS" ;
VAL_ 782 PARK_tireFitment 3 "SNA" 2 "NOT_USED" 1 "STAGGERED" 0 "SQUARE" ;
VAL_ 782 PARK_rackDetected 3 "SNA" 2 "RACK_DETECTED" 1 "NO_RACK" 0 "UNKNOWN" ;
VAL_ 782 PARK_sdiActive 1 "SDI_ENABLED" 0 "SDI_DISABLED" ;
VAL_ 782 PARK_sdiNoise 3 "SDI_NOISE_SNA" 2 "SDI_NOISE_RAIN" 1 "SDI_NOISE_HIGH" 0 "SDI_NOISE_NOMINAL" ;
VAL_ 782 PARK_sdiBlindSpotRight 3 "SNA" 2 "UNUSED" 1 "WARNING" 0 "NO_WARNING" ;
VAL_ 782 PARK_sdiBlindSpotLeft 3 "SNA" 2 "UNUSED" 1 "WARNING" 0 "NO_WARNING" ;
VAL_ 782 PARK_sensorType 3 "SNA" 2 "VALEO_HP" 1 "VALEO_HPFL" 0 "NONE" ;
VAL_ 1329 RADC_infoIndex 20 "Mux20" 19 "Mux19" 13 "Mux13" 11 "Mux11" 10 "Mux10" ;
VAL_ 1329 RADC_infoBuildType 4 "INFO_MFG_BUILD" 3 "INFO_TRACEABLE_CI_BUILD" 2 "INFO_LOCAL_BUILD" 1 "INFO_PLATFORM_BUILD" 0 "INFO_UNKNOWN_BUILD" ;
VAL_ 257 RCM_yawRate -32768 "SNA" ;
VAL_ 257 RCM_pitchRate -16384 "SNA" ;
VAL_ 257 RCM_rollRate -16384 "SNA" ;
VAL_ 257 RCM_rollRateQF 3 "FAULTED" 2 "TEMP_INVALID" 1 "VALID" 0 "INIT" ;
VAL_ 257 RCM_yawRateQF 1 "NOT_FAULTED" 0 "FAULTED" ;
VAL_ 257 RCM_pitchRateQF 3 "FAULTED" 2 "TEMP_INVALID" 1 "VALID" 0 "INIT" ;
VAL_ 273 RCM_longitudinalAccel -32768 "SNA" ;
VAL_ 273 RCM_lateralAccel -32768 "SNA" ;
VAL_ 273 RCM_verticalAccel -32768 "SNA" ;
VAL_ 273 RCM_longitudinalAccelQF 1 "NOT_FAULTED" 0 "FAULTED" ;
VAL_ 273 RCM_lateralAccelQF 1 "NOT_FAULTED" 0 "FAULTED" ;
VAL_ 273 RCM_verticalAccelQF 1 "NOT_FAULTED" 0 "FAULTED" ;
VAL_ 273 RCM_CGTranslationFault 1 "RCM_COG_TRANSLATION_FAULTED" 0 "RCM_COG_TRANSLATION_NOT_FAULTED" ;
VAL_ 849 RCM_infoIndex 255 "END" 31 "SUBCOMPONENT_GITHASH" 30 "PACKAGE_SN_8_14" 29 "PACKAGE_SN_1_7" 27 "PACKAGE_PN_15_20" 26 "PACKAGE_PN_8_14" 25 "PACKAGE_PN_1_7" 23 "SUBCOMPONENT2" 22 "VARIANTCRC" 20 "UDS_PROTOCOL_BOOTCRC" 19 "VERSION_DEPRECATED" 18 "BOOTLOADER_GITHASH" 17 "APP_GITHASH" 16 "SUBCOMPONENT" 15 "BOOTLOADER_CRC" 14 "BOOTLOADER_SVN" 13 "APP_CRC" 11 "PCBAID_ASSYID_USAGEID" 10 "BUILD_HWID_COMPONENTID" 9 "DEPRECATED_9" 8 "DEPRECATED_8" 7 "DEPRECATED_7" 6 "DEPRECATED_6" 5 "DEPRECATED_5" 4 "DEPRECATED_4" 3 "DEPRECATED_3" 2 "DEPRECATED_2" 1 "DEPRECATED_1" 0 "DEPRECATED_0" ;
VAL_ 849 RCM_infoBuildType 4 "INFO_MFG_BUILD" 3 "INFO_TRACEABLE_CI_BUILD" 2 "INFO_LOCAL_BUILD" 1 "INFO_PLATFORM_BUILD" 0 "INFO_UNKNOWN_BUILD" ;
VAL_ 529 RCM_armStatus 3 "SNA" 2 "ARMED_WITH_NOFIRE_CAL" 1 "RCM_ARMED" 0 "RCM_UNARMED" ;
VAL_ 529 RCM_warningIndicatorState 3 "SNA" 1 "RCM_WARNING_INDICATOR_ON" 0 "RCM_WARNING_INDICATOR_OFF" ;
VAL_ 529 RCM_passAirbagIndicatorRequest 3 "SNA" 1 "RCM_PASSENGER_AIRBAG_INDICATOR_OFF" 0 "RCM_PASSENGER_AIRBAG_INDICATOR_ON" ;
VAL_ 529 RCM_airbagCutoffStatus 3 "SNA" 1 "RCM_PASSENGER_AIRBAG_DISABLED" 0 "RCM_PASSENGER_AIRBAG_ENABLED" ;
VAL_ 529 RCM_alrSwitchStatus 3 "SNA" 2 "RCM_ALR_FAULTED" 1 "RCM_ALR_ENGAGED" 0 "RCM_ALR_NOT_ENGAGED" ;
VAL_ 529 RCM_vinLearnFlag 3 "SNA" 2 "RCM_VIN_STORED_MISMATCH" 1 "RCM_VIN_STORED" 0 "RCM_VIN_NOT_STORED" ;
VAL_ 529 RCM_seatTrackPositionDrvr 3 "SNA" 2 "RCM_SEAT_POSITION_FAULTED" 1 "RCM_SEAT_POSITION_FAR" 0 "RCM_SEAT_POSITION_NEAR" ;
VAL_ 529 RCM_seatTrackPositionPass 3 "SNA" 2 "RCM_SEAT_POSITION_FAULTED" 1 "RCM_SEAT_POSITION_FAR" 0 "RCM_SEAT_POSITION_NEAR" ;
VAL_ 529 RCM_edr1State 3 "RCM_EDR_UNAVAILABLE" 2 "RCM_EDR_LOCKED" 1 "RCM_EDR_STORED" 0 "RCM_EDR_EMPTY" ;
VAL_ 529 RCM_edr2State 3 "RCM_EDR_UNAVAILABLE" 2 "RCM_EDR_LOCKED" 1 "RCM_EDR_STORED" 0 "RCM_EDR_EMPTY" ;
VAL_ 529 RCM_keepPowerReason 8 "RCM_KEEP_POWER_REASON_SNA" 7 "RCM_INVALID_POWER_OFF_REQUEST" 6 "RCM_INITIALIZATION_PHASE" 5 "RCM_CANNOT_POWER_DOWN" 4 "RCM_EDR_UPLOADING" 3 "RCM_EDR_STORING_TO_EEPROM" 2 "RCM_CRASH_ALGO_ACTIVE" 1 "RCM_IN_IDLE_MODE" 0 "RCM_NO_KEEP_POWER_REQUEST" ;
VAL_ 529 RCM_imuOffsetLearnState 3 "IMU_OFFSETS_UNABLE_TO_LEARN" 2 "IMU_FAST_LEARNING_TIME" 1 "IMU_SLOW_LEARNING_DISTANCE" 0 "IMU_OFFSET_LEARNING_OFF" ;
VAL_ 529 RCM_edr3State 3 "RCM_EDR_UNAVAILABLE" 2 "RCM_EDR_LOCKED" 1 "RCM_EDR_STORED" 0 "RCM_EDR_EMPTY" ;
VAL_ 529 RCM_driverOrientationInitStatus 7 "SNA" 4 "RCM_DRIVER_ORIENTATION_MISMATCH_DEFAULT_RHD" 3 "RCM_DRIVER_ORIENTATION_MISMATCH_DEFAULT_LHD" 2 "RCM_DRIVER_ORIENTATION_MATCHED_RHD" 1 "RCM_DRIVER_ORIENTATION_MATCHED_LHD" 0 "RCM_DRIVER_ORIENTATION_INIT_NOT_COMPLETE" ;
VAL_ 529 RCM_occupantClassificationSource 1 "VCRIGHT_CLASSIFICATION_SOURCE" 0 "OCS1P_CLASSIFICATION_SOURCE" ;
VAL_ 529 RCM_pedProEDR1State 3 "RCM_EDR_UNAVAILABLE" 2 "RCM_EDR_LOCKED" 1 "RCM_EDR_STORED" 0 "RCM_EDR_EMPTY" ;
VAL_ 529 RCM_pedProEDR2State 3 "RCM_EDR_UNAVAILABLE" 2 "RCM_EDR_LOCKED" 1 "RCM_EDR_STORED" 0 "RCM_EDR_EMPTY" ;
VAL_ 879 TPMS_learningStatus 3 "PASSED" 2 "STOPPED" 1 "ONGOING" 0 "FAILED" ;
VAL_ 879 TPMS_localisationStatus 3 "PASSED" 2 "STOPPED" 1 "ONGOING" 0 "FAILED" ;
VAL_ 799 TPMS_pressureFL 255 "SNA" 254 "OVER_RANGE" ;
VAL_ 799 TPMS_temperatureFL 255 "TPMS_TEMPERATURE_SNA" ;
VAL_ 799 TPMS_pressureFR 255 "SNA" 254 "OVER_RANGE" ;
VAL_ 799 TPMS_temperatureFR 255 "TPMS_TEMPERATURE_SNA" ;
VAL_ 799 TPMS_pressureRL 255 "SNA" 254 "OVER_RANGE" ;
VAL_ 799 TPMS_temperatureRL 255 "TPMS_TEMPERATURE_SNA" ;
VAL_ 799 TPMS_pressureRR 255 "SNA" 254 "OVER_RANGE" ;
VAL_ 799 TPMS_temperatureRR 255 "TPMS_TEMPERATURE_SNA" ;
VAL_ 1519 TPMS_infoIndex 255 "END" 31 "SUBCOMPONENT_GITHASH" 30 "PACKAGE_SN_8_14" 29 "PACKAGE_SN_1_7" 27 "PACKAGE_PN_15_20" 26 "PACKAGE_PN_8_14" 25 "PACKAGE_PN_1_7" 23 "SUBCOMPONENT2" 22 "VARIANTCRC" 20 "UDS_PROTOCOL_BOOTCRC" 19 "VERSION_DEPRECATED" 18 "BOOTLOADER_GITHASH" 17 "APP_GITHASH" 16 "SUBCOMPONENT" 15 "BOOTLOADER_CRC" 14 "BOOTLOADER_SVN" 13 "APP_CRC" 11 "PCBAID_ASSYID_USAGEID" 10 "BUILD_HWID_COMPONENTID" 9 "DEPRECATED_9" 8 "DEPRECATED_8" 7 "DEPRECATED_7" 6 "DEPRECATED_6" 5 "DEPRECATED_5" 4 "DEPRECATED_4" 3 "DEPRECATED_3" 2 "DEPRECATED_2" 1 "DEPRECATED_1" 0 "DEPRECATED_0" ;
VAL_ 659 UI_steeringTuneRequest 2 "STEERING_TUNE_SPORT" 1 "STEERING_TUNE_STANDARD" 0 "STEERING_TUNE_COMFORT" ;
VAL_ 659 UI_tractionControlMode 7 "TC_SLIPPERY_SURFACE_SELECTED" 6 "TC_OFFROAD_ASSIST_SELECTED" 5 "TC_DYNO_MODE_SELECTED" 4 "TC_ROLLS_MODE_SELECTED" 3 "TC_DEV_MODE_2_SELECTED" 2 "TC_DEV_MODE_1_SELECTED" 1 "TC_SLIP_START_SELECTED" 0 "TC_NORMAL_SELECTED" ;
VAL_ 659 UI_parkBrakeRequest 3 "PARK_BRAKE_REQUEST_SNA" 1 "PARK_BRAKE_REQUEST_PRESSED" 0 "PARK_BRAKE_REQUEST_IDLE" ;
VAL_ 659 UI_winchModeRequest 3 "WINCH_MODE_DIALOGUE_OPEN" 2 "WINCH_MODE_EXIT" 1 "WINCH_MODE_ENTER" 0 "WINCH_MODE_IDLE" ;
VAL_ 659 UI_trailerMode 1 "TRAILER_MODE_ON" 0 "TRAILER_MODE_OFF" ;
VAL_ 659 UI_accOvertakeEnable 3 "SNA" 1 "ACC_OVERTAKE_ON" 0 "ACC_OVERTAKE_OFF" ;
VAL_ 659 UI_aebEnable 3 "SNA" 1 "AEB_ON" 0 "AEB_OFF" ;
VAL_ 659 UI_aesEnable 3 "SNA" 1 "AES_ON" 0 "AES_OFF" ;
VAL_ 659 UI_ahlbEnable 3 "SNA" 1 "AHLB_ON" 0 "AHLB_OFF" ;
VAL_ 659 UI_autoLaneChangeEnable 3 "SNA" 1 "ON" 0 "OFF" ;
VAL_ 659 UI_autoParkRequest 15 "SNA" 12 "BEGIN_PARKING" 11 "RESUME" 10 "PAUSE" 9 "SEARCH" 8 "COMPLETE" 7 "ABORT" 6 "PARALLEL_PULL_OUT_TO_RIGHT" 5 "PARALLEL_PULL_OUT_TO_LEFT" 4 "PARK_RIGHT_CROSS" 3 "PARK_RIGHT_PARALLEL" 2 "PARK_LEFT_CROSS" 1 "PARK_LEFT_PARALLEL" 0 "NONE" ;
VAL_ 659 UI_bsdEnable 3 "SNA" 1 "BSD_ON" 0 "BSD_OFF" ;
VAL_ 659 UI_fcwEnable 3 "SNA" 1 "FCW_ON" 0 "FCW_OFF" ;
VAL_ 659 UI_fcwSensitivity 3 "SNA" 2 "AEB_SENSITIVITY_LATE" 1 "AEB_SENSITIVITY_AVERAGE" 0 "AEB_SENSITIVITY_EARLY" ;
VAL_ 659 UI_latControlEnable 3 "LATERAL_CONTROL_SNA" 2 "LATERAL_CONTROL_UNAVAILABLE" 1 "LATERAL_CONTROL_ON" 0 "LATERAL_CONTROL_OFF" ;
VAL_ 659 UI_ldwEnable 3 "SNA" 1 "LDW_TRIGGERS_HAPTIC" 0 "NO_HAPTIC" ;
VAL_ 1016 UI_lssLkaEnabled 1 "LKA_ON" 0 "LKA_OFF" ;
VAL_ 1016 UI_lssLdwEnabled 1 "LDW_ON" 0 "LDW_OFF" ;
VAL_ 1016 UI_driveOnMapsEnable 1 "DOM_ON" 0 "DOM_OFF" ;
VAL_ 1016 UI_lssElkEnabled 1 "ELK_ON" 0 "ELK_OFF" ;
VAL_ 1016 UI_selfParkRequest 15 "SNA" 12 "SMART_SUMMON_NO_OP" 11 "SMART_SUMMON" 10 "AUTO_SUMMON_PRIMED" 9 "AUTO_SUMMON_CANCEL" 8 "AUTO_SUMMON_REVERSE" 7 "AUTO_SUMMON_FORWARD" 6 "RESUME" 5 "PAUSE" 4 "PRIME" 3 "ABORT" 2 "SELF_PARK_REVERSE" 1 "SELF_PARK_FORWARD" 0 "NONE" ;
VAL_ 1016 UI_followNavRouteEnable 1 "NAV_ROUTE_ON" 0 "NAV_ROUTE_OFF" ;
VAL_ 1016 UI_ulcSpeedConfig 3 "SPEED_BASED_ULC_MAD_MAX" 2 "SPEED_BASED_ULC_AVERAGE" 1 "SPEED_BASED_ULC_MILD" 0 "SPEED_BASED_ULC_DISABLED" ;
VAL_ 1016 UI_smartSummonType 2 "SMART_AUTOPARK" 1 "FIND_ME" 0 "PIN_DROP" ;
VAL_ 568 UI_roadClass 6 "CLASS_6_MINOR" 5 "CLASS_5" 4 "CLASS_4" 3 "CLASS_3" 2 "CLASS_2" 1 "CLASS_1_MAJOR" 0 "UNKNOWN_INVALID_SNA" ;
VAL_ 760 UI_mapSpeedLimitUnits 1 "KPH" 0 "MPH" ;
VAL_ 760 UI_conditionalSpeedLimit 31 "SNA" ;
VAL_ 1011 UI_odometer 16777215 "SNA" ;
VAL_ 723 UI_isSunUp 3 "SUN_SNA" 1 "SUN_UP" 0 "SUN_DOWN" ;
VAL_ 723 UI_solarElevationAngle 127 "SNA" ;
VAL_ 851 UI_factoryReset 3 "CUSTOMER" 2 "DIAGNOSTIC" 1 "DEVELOPER" 0 "NONE_SNA" ;
VAL_ 851 UI_cellNetworkTechnology 15 "CELL_NETWORK_SNA" 14 "CELL_NETWORK_NGRAN" 13 "CELL_NETWORK_5GSA" 12 "CELL_NETWORK_5GNSA" 11 "CELL_NETWORK_LTE5GCN" 10 "CELL_NETWORK_WCDMA" 9 "CELL_NETWORK_CDMA" 8 "CELL_NETWORK_GSM" 7 "CELL_NETWORK_LTE" 6 "CELL_NETWORK_HSPA" 5 "CELL_NETWORK_HSUPA" 4 "CELL_NETWORK_HSDPA" 3 "CELL_NETWORK_UMTS" 2 "CELL_NETWORK_EDGE" 1 "CELL_NETWORK_GPRS" 0 "CELL_NETWORK_NONE" ;
VAL_ 851 UI_cellSignalBars 7 "SNA" 5 "FIVE" 4 "FOUR" 3 "THREE" 2 "TWO" 1 "ONE" 0 "ZERO" ;
VAL_ 851 UI_trailerModeTelltale 3 "TRAILER_MODE_TELLTALE_RED" 2 "TRAILER_MODE_TELLTALE_YELLOW" 1 "TRAILER_MODE_TELLTALE_BLUE" 0 "TRAILER_MODE_TELLTALE_OFF" ;
VAL_ 807 USM_infoIndex 255 "END" 41 "SUBCOMPONENT14" 40 "SUBCOMPONENT13" 39 "SUBCOMPONENT12" 38 "SUBCOMPONENT11" 37 "SUBCOMPONENT10" 36 "SUBCOMPONENT9" 35 "SUBCOMPONENT8" 34 "SUBCOMPONENT7" 33 "SUBCOMPONENT6" 32 "SUBCOMPONENT5" 31 "SUBCOMPONENT4" 24 "SUBCOMPONENT3" 23 "SUBCOMPONENT2" 20 "UDS_PROTOCOL_BOOTCRC" 19 "VERSION_DEPRECATED" 18 "BOOTLOADER_GITHASH" 17 "APP_GITHASH" 16 "SUBCOMPONENT1" 15 "BOOTLOADER_CRC" 14 "BOOTLOADER_SVN" 13 "APP_CRC" 11 "PCBAID_ASSYID_USAGEID" 10 "BUILD_HWID_COMPONENTID" 9 "DEPRECATED_9" 8 "DEPRECATED_8" 7 "DEPRECATED_7" 6 "DEPRECATED_6" 5 "DEPRECATED_5" 4 "DEPRECATED_4" 3 "DEPRECATED_3" 2 "DEPRECATED_2" 1 "DEPRECATED_1" 0 "DEPRECATED_0" ;
VAL_ 807 USM_infoBuildType 4 "INFO_MFG_BUILD" 3 "INFO_TRACEABLE_CI_BUILD" 2 "INFO_LOCAL_BUILD" 1 "INFO_PLATFORM_BUILD" 0 "INFO_UNKNOWN_BUILD" ;
VAL_ 807 USM_infoAssemblyId 255 "ASSEMBLY_SNA" 1 "ASSEMBLY1" ;
